VERSION "ChassisCANhs"

NS_ :

BS_:

BU_: CUST USS_ECU HMI PF_PP
VAL_TABLE_ VehStandStill 3 "not used" 2 "Standstill" 1 "no Standstill" 0 "None / unknown" ;
VAL_TABLE_ GearStatus 15 "not used" 14 "not used" 13 "not used" 12 "not used" 11 "not used" 10 "not used" 9 "not used" 8 "not used" 7 "not used" 6 "not used" 5 "not used" 4 "not used" 3 "Drive" 2 "Neutral" 1 "Reverse" 0 "Park" ;
VAL_TABLE_ WheelDirection 3 "not used" 2 "Stop" 1 "Backard" 0 "Forward" ;

BO_ 3221225472 VECTOR__INDEPENDENT_SIG_MSG: 0 Vector__XXX
 SG_ MAP_NumberOfObjects1620 : 0|4@1+ (1,0) [0|15] "" Vector__XXX
 SG_ MAP_20_ObjDist : 0|10@1+ (1,0) [0|1000] "cm" Vector__XXX
 SG_ MAP_19_ObjDist : 0|10@1+ (1,0) [0|1000] "cm" Vector__XXX
 SG_ MAP_18_ObjDist : 0|10@1+ (1,0) [0|1000] "cm" Vector__XXX
 SG_ MAP_17_ObjDist : 0|10@1+ (1,0) [0|1000] "cm" Vector__XXX
 SG_ MAP_16_ObjDist : 0|10@1+ (1,0) [0|1000] "cm" Vector__XXX
 SG_ Multiplex_ID_OBJ_DIST_2 : 0|2@1+ (1,0) [0|0] "" Vector__XXX
 SG_ MAP_06_ObjDist : 0|10@1+ (1,0) [0|1000] "cm" Vector__XXX
 SG_ MAP_NumberOfObjects0610 : 0|4@1+ (1,0) [0|15] "" Vector__XXX
 SG_ MAP_10_ObjDist : 0|10@1+ (1,0) [0|1000] "cm" Vector__XXX
 SG_ MAP_09_ObjDist : 0|10@1+ (1,0) [0|1000] "cm" Vector__XXX
 SG_ MAP_08_ObjDist : 0|10@1+ (1,0) [0|1000] "cm" Vector__XXX
 SG_ MAP_07_ObjDist : 0|10@1+ (1,0) [0|1000] "cm" Vector__XXX
 SG_ MAP_NumberOfObjects0105 : 0|4@1+ (1,0) [0|15] "" Vector__XXX
 SG_ MAP_NumberOfObjects1115 : 0|4@1+ (1,0) [0|15] "" Vector__XXX
 SG_ MAP_15_ObjDist : 0|10@1+ (1,0) [0|1000] "cm" Vector__XXX
 SG_ MAP_14_ObjDist : 0|10@1+ (1,0) [0|1000] "cm" Vector__XXX
 SG_ MAP_13_ObjDist : 0|10@1+ (1,0) [0|1000] "cm" Vector__XXX
 SG_ MAP_12_ObjDist : 0|10@1+ (1,0) [0|1000] "cm" Vector__XXX
 SG_ MAP_11_ObjDist : 0|10@1+ (1,0) [0|1000] "cm" Vector__XXX
 SG_ Multiplex_ID_OBJ_DIST_1 : 0|2@1+ (1,0) [0|0] "" Vector__XXX
 SG_ MAP_05_ObjDist : 0|10@1+ (1,0) [0|1000] "cm" Vector__XXX
 SG_ MAP_04_ObjDist : 0|10@1+ (1,0) [0|1000] "cm" Vector__XXX
 SG_ MAP_03_ObjDist : 0|10@1+ (1,0) [0|1000] "cm" Vector__XXX
 SG_ MAP_02_ObjDist : 0|10@1+ (1,0) [0|1000] "cm" Vector__XXX
 SG_ MAP_01_ObjDist : 0|10@1+ (1,0) [0|1000] "cm" Vector__XXX
 SG_ sens11Amplitude3 : 0|6@1+ (1,0) [0|63] "" Vector__XXX
 SG_ sens11De3Distance : 0|10@1+ (1,0) [0|1023] "cm" Vector__XXX
 SG_ sens10Amplitude3 : 0|6@1+ (1,0) [0|63] "" Vector__XXX
 SG_ sens10De3Distance : 0|10@1+ (1,0) [0|1023] "cm" Vector__XXX
 SG_ sens12Amplitude3 : 0|6@1+ (1,0) [0|63] "" Vector__XXX
 SG_ sens12De3Distance : 0|10@1+ (1,0) [0|1023] "cm" Vector__XXX
 SG_ sens09Amplitude3 : 0|6@1+ (1,0) [0|63] "" Vector__XXX
 SG_ sens09De3Distance : 0|10@1+ (1,0) [0|1023] "cm" Vector__XXX
 SG_ sens08Amplitude3 : 0|6@1+ (1,0) [0|63] "" Vector__XXX
 SG_ sens08De3Distance : 0|10@1+ (1,0) [0|1023] "cm" Vector__XXX
 SG_ sens07Amplitude3 : 0|6@1+ (1,0) [0|63] "" Vector__XXX
 SG_ sens07De3Distance : 0|10@1+ (1,0) [0|1023] "cm" Vector__XXX
 SG_ sens06Amplitude3 : 0|6@1+ (1,0) [0|63] "" Vector__XXX
 SG_ sens06De3Distance : 0|10@1+ (1,0) [0|1023] "cm" Vector__XXX
 SG_ sens05Amplitude3 : 0|6@1+ (1,0) [0|63] "" Vector__XXX
 SG_ sens05De3Distance : 0|10@1+ (1,0) [0|1023] "cm" Vector__XXX
 SG_ sens03De3Distance : 0|10@1+ (1,0) [0|1023] "cm" Vector__XXX
 SG_ sens03Amplitude3 : 0|6@1+ (1,0) [0|63] "" Vector__XXX
 SG_ sens02Amplitude3 : 0|6@1+ (1,0) [0|63] "" Vector__XXX
 SG_ sens02De3Distance : 0|10@1+ (1,0) [0|1023] "cm" Vector__XXX
 SG_ sens04Amplitude3 : 0|6@1+ (1,0) [0|63] "" Vector__XXX
 SG_ sens04De3Distance : 0|10@1+ (1,0) [0|1023] "cm" Vector__XXX
 SG_ sens01Amplitude3 : 0|6@1+ (1,0) [0|63] "" Vector__XXX
 SG_ sens01De3Distance : 0|10@1+ (1,0) [0|1023] "cm" Vector__XXX
 SG_ MAP_13_NewObj : 0|1@1+ (1,0) [0|1] "" Vector__XXX
 SG_ MAP_03_NewObj : 0|1@1+ (1,0) [0|1] "" Vector__XXX
 SG_ MAP_12_NewObj : 0|1@1+ (1,0) [0|1] "" Vector__XXX
 SG_ MAP_02_NewObj : 0|1@1+ (1,0) [0|1] "" Vector__XXX
 SG_ MAP_11_NewObj : 0|1@1+ (1,0) [0|1] "" Vector__XXX
 SG_ MAP_01_NewObj : 0|1@1+ (1,0) [0|1] "" Vector__XXX
 SG_ MAP_20_NewObj : 0|1@1+ (1,0) [0|1] "" Vector__XXX
 SG_ MAP_10_NewObj : 0|1@1+ (1,0) [0|1] "" Vector__XXX
 SG_ MAP_19_NewObj : 0|1@1+ (1,0) [0|1] "" Vector__XXX
 SG_ MAP_09_NewObj : 0|1@1+ (1,0) [0|1] "" Vector__XXX
 SG_ MAP_18_NewObj : 0|1@1+ (1,0) [0|1] "" Vector__XXX
 SG_ MAP_08_NewObj : 0|1@1+ (1,0) [0|1] "" Vector__XXX
 SG_ MAP_17_NewObj : 0|1@1+ (1,0) [0|1] "" Vector__XXX
 SG_ MAP_07_NewObj : 0|1@1+ (1,0) [0|1] "" Vector__XXX
 SG_ MAP_16_NewObj : 0|1@1+ (1,0) [0|1] "" Vector__XXX
 SG_ MAP_06_NewObj : 0|1@1+ (1,0) [0|1] "" Vector__XXX
 SG_ MAP_15_NewObj : 0|1@1+ (1,0) [0|1] "" Vector__XXX
 SG_ MAP_05_NewObj : 0|1@1+ (1,0) [0|1] "" Vector__XXX
 SG_ MAP_14_NewObj : 0|1@1+ (1,0) [0|1] "" Vector__XXX
 SG_ MAP_04_NewObj : 0|1@1+ (1,0) [0|1] "" Vector__XXX
 SG_ MessageCounter_01_Map_Obj_11 : 0|2@1+ (1,0) [0|3] "" Vector__XXX
 SG_ MessageCounter_00_Map_Obj_10 : 0|2@1+ (1,0) [0|3] "" Vector__XXX
 SG_ MessageCounter_00_Map_Obj_09 : 0|2@1+ (1,0) [0|3] "" Vector__XXX
 SG_ MessageCounter_00_Map_Obj_08 : 0|2@1+ (1,0) [0|3] "" Vector__XXX
 SG_ MessageCounter_00_Map_Obj_07 : 0|2@1+ (1,0) [0|3] "" Vector__XXX
 SG_ MessageCounter_00_Map_Obj_06 : 0|2@1+ (1,0) [0|3] "" Vector__XXX
 SG_ MessageCounter_00_Map_Obj_05 : 0|2@1+ (1,0) [0|3] "" Vector__XXX
 SG_ MessageCounter_00_Map_Obj_04 : 0|2@1+ (1,0) [0|3] "" Vector__XXX
 SG_ MessageCounter_00_Map_Obj_03 : 0|2@1+ (1,0) [0|3] "" Vector__XXX
 SG_ MessageCounter_00_Map_Obj_02 : 0|2@1+ (1,0) [0|3] "" Vector__XXX

BO_ 2033 USS_diag_IDs: 8 USS_ECU
 SG_ CanIDDiagResp : 32|32@1+ (1,0) [0|4294967295] "" Vector__XXX
 SG_ CanIDDiagTstReq : 0|32@1+ (1,0) [0|4294967295] "" Vector__XXX

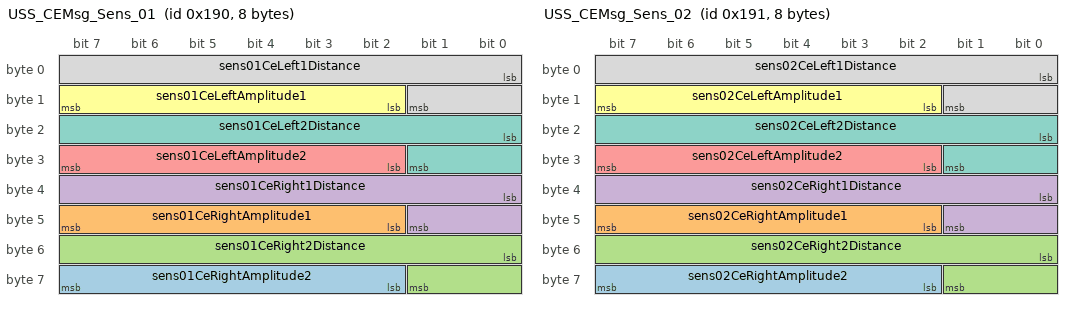
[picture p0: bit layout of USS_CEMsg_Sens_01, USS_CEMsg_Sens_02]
BO_ 400 USS_CEMsg_Sens_01: 8 USS_ECU
 SG_ sens01CeRightAmplitude2 : 58|6@1+ (1,0) [0|63] ""  CUST
 SG_ sens01CeRightAmplitude1 : 42|6@1+ (1,0) [0|63] ""  CUST
 SG_ sens01CeRight2Distance : 48|10@1+ (1,0) [0|1023] "cm"  CUST
 SG_ sens01CeRight1Distance : 32|10@1+ (1,0) [0|1023] "cm"  CUST
 SG_ sens01CeLeftAmplitude2 : 26|6@1+ (1,0) [0|63] ""  CUST
 SG_ sens01CeLeftAmplitude1 : 10|6@1+ (1,0) [0|63] ""  CUST
 SG_ sens01CeLeft2Distance : 16|10@1+ (1,0) [0|1023] "cm"  CUST
 SG_ sens01CeLeft1Distance : 0|10@1+ (1,0) [0|1023] "cm"  CUST

BO_ 401 USS_CEMsg_Sens_02: 8 USS_ECU
 SG_ sens02CeRightAmplitude2 : 58|6@1+ (1,0) [0|63] ""  CUST
 SG_ sens02CeRightAmplitude1 : 42|6@1+ (1,0) [0|63] ""  CUST
 SG_ sens02CeRight2Distance : 48|10@1+ (1,0) [0|1023] "cm"  CUST
 SG_ sens02CeRight1Distance : 32|10@1+ (1,0) [0|1023] "cm"  CUST
 SG_ sens02CeLeftAmplitude2 : 26|6@1+ (1,0) [0|63] ""  CUST
 SG_ sens02CeLeftAmplitude1 : 10|6@1+ (1,0) [0|63] ""  CUST
 SG_ sens02CeLeft2Distance : 16|10@1+ (1,0) [0|1023] "cm"  CUST
 SG_ sens02CeLeft1Distance : 0|10@1+ (1,0) [0|1023] "cm"  CUST

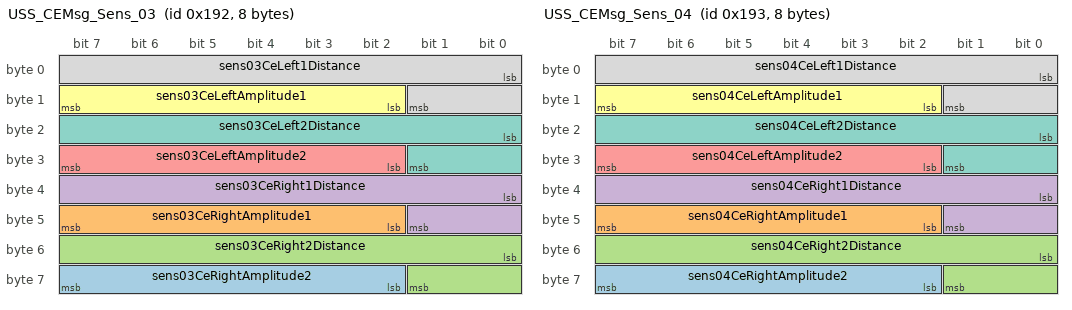
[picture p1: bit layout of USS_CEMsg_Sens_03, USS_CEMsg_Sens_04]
BO_ 402 USS_CEMsg_Sens_03: 8 USS_ECU
 SG_ sens03CeRightAmplitude2 : 58|6@1+ (1,0) [0|63] ""  CUST
 SG_ sens03CeRightAmplitude1 : 42|6@1+ (1,0) [0|63] ""  CUST
 SG_ sens03CeRight2Distance : 48|10@1+ (1,0) [0|1023] "cm"  CUST
 SG_ sens03CeRight1Distance : 32|10@1+ (1,0) [0|1023] "cm"  CUST
 SG_ sens03CeLeftAmplitude2 : 26|6@1+ (1,0) [0|63] ""  CUST
 SG_ sens03CeLeftAmplitude1 : 10|6@1+ (1,0) [0|63] ""  CUST
 SG_ sens03CeLeft2Distance : 16|10@1+ (1,0) [0|1023] "cm"  CUST
 SG_ sens03CeLeft1Distance : 0|10@1+ (1,0) [0|1023] "cm"  CUST

BO_ 403 USS_CEMsg_Sens_04: 8 USS_ECU
 SG_ sens04CeRightAmplitude2 : 58|6@1+ (1,0) [0|63] ""  CUST
 SG_ sens04CeRightAmplitude1 : 42|6@1+ (1,0) [0|63] ""  CUST
 SG_ sens04CeRight2Distance : 48|10@1+ (1,0) [0|1023] "cm"  CUST
 SG_ sens04CeRight1Distance : 32|10@1+ (1,0) [0|1023] "cm"  CUST
 SG_ sens04CeLeftAmplitude2 : 26|6@1+ (1,0) [0|63] ""  CUST
 SG_ sens04CeLeftAmplitude1 : 10|6@1+ (1,0) [0|63] ""  CUST
 SG_ sens04CeLeft2Distance : 16|10@1+ (1,0) [0|1023] "cm"  CUST
 SG_ sens04CeLeft1Distance : 0|10@1+ (1,0) [0|1023] "cm"  CUST

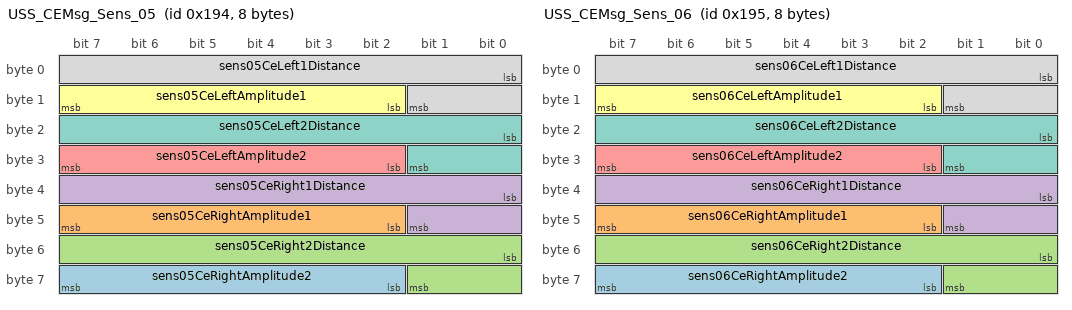
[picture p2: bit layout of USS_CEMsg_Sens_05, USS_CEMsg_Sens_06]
BO_ 404 USS_CEMsg_Sens_05: 8 USS_ECU
 SG_ sens05CeRightAmplitude2 : 58|6@1+ (1,0) [0|63] ""  CUST
 SG_ sens05CeRightAmplitude1 : 42|6@1+ (1,0) [0|63] ""  CUST
 SG_ sens05CeRight2Distance : 48|10@1+ (1,0) [0|1023] "cm"  CUST
 SG_ sens05CeRight1Distance : 32|10@1+ (1,0) [0|1023] "cm"  CUST
 SG_ sens05CeLeftAmplitude2 : 26|6@1+ (1,0) [0|63] ""  CUST
 SG_ sens05CeLeftAmplitude1 : 10|6@1+ (1,0) [0|63] ""  CUST
 SG_ sens05CeLeft2Distance : 16|10@1+ (1,0) [0|1023] "cm"  CUST
 SG_ sens05CeLeft1Distance : 0|10@1+ (1,0) [0|1023] "cm"  CUST

BO_ 405 USS_CEMsg_Sens_06: 8 USS_ECU
 SG_ sens06CeRightAmplitude2 : 58|6@1+ (1,0) [0|63] ""  CUST
 SG_ sens06CeRightAmplitude1 : 42|6@1+ (1,0) [0|63] ""  CUST
 SG_ sens06CeRight2Distance : 48|10@1+ (1,0) [0|1023] "cm"  CUST
 SG_ sens06CeRight1Distance : 32|10@1+ (1,0) [0|1023] "cm"  CUST
 SG_ sens06CeLeftAmplitude2 : 26|6@1+ (1,0) [0|63] ""  CUST
 SG_ sens06CeLeftAmplitude1 : 10|6@1+ (1,0) [0|63] ""  CUST
 SG_ sens06CeLeft2Distance : 16|10@1+ (1,0) [0|1023] "cm"  CUST
 SG_ sens06CeLeft1Distance : 0|10@1+ (1,0) [0|1023] "cm"  CUST

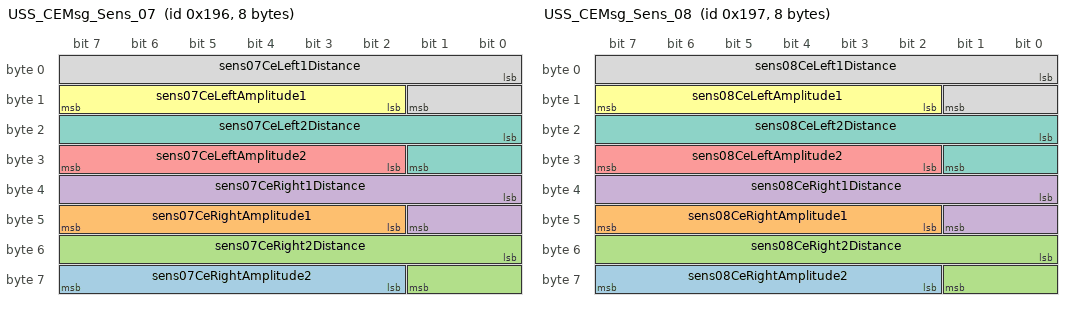
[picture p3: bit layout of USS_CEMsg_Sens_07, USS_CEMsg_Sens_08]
BO_ 406 USS_CEMsg_Sens_07: 8 USS_ECU
 SG_ sens07CeRightAmplitude2 : 58|6@1+ (1,0) [0|63] ""  CUST
 SG_ sens07CeRightAmplitude1 : 42|6@1+ (1,0) [0|63] ""  CUST
 SG_ sens07CeRight2Distance : 48|10@1+ (1,0) [0|1023] "cm"  CUST
 SG_ sens07CeRight1Distance : 32|10@1+ (1,0) [0|1023] "cm"  CUST
 SG_ sens07CeLeftAmplitude2 : 26|6@1+ (1,0) [0|63] ""  CUST
 SG_ sens07CeLeftAmplitude1 : 10|6@1+ (1,0) [0|63] ""  CUST
 SG_ sens07CeLeft2Distance : 16|10@1+ (1,0) [0|1023] "cm"  CUST
 SG_ sens07CeLeft1Distance : 0|10@1+ (1,0) [0|1023] "cm"  CUST

BO_ 407 USS_CEMsg_Sens_08: 8 USS_ECU
 SG_ sens08CeRightAmplitude2 : 58|6@1+ (1,0) [0|63] ""  CUST
 SG_ sens08CeRightAmplitude1 : 42|6@1+ (1,0) [0|63] ""  CUST
 SG_ sens08CeRight2Distance : 48|10@1+ (1,0) [0|1023] "cm"  CUST
 SG_ sens08CeRight1Distance : 32|10@1+ (1,0) [0|1023] "cm"  CUST
 SG_ sens08CeLeftAmplitude2 : 26|6@1+ (1,0) [0|63] ""  CUST
 SG_ sens08CeLeftAmplitude1 : 10|6@1+ (1,0) [0|63] ""  CUST
 SG_ sens08CeLeft2Distance : 16|10@1+ (1,0) [0|1023] "cm"  CUST
 SG_ sens08CeLeft1Distance : 0|10@1+ (1,0) [0|1023] "cm"  CUST

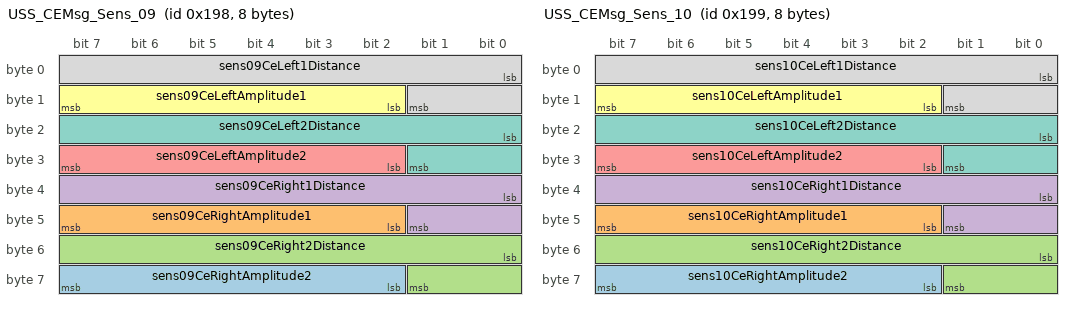
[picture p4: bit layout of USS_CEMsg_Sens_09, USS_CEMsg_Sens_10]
BO_ 408 USS_CEMsg_Sens_09: 8 USS_ECU
 SG_ sens09CeRightAmplitude2 : 58|6@1+ (1,0) [0|63] ""  CUST
 SG_ sens09CeRightAmplitude1 : 42|6@1+ (1,0) [0|63] ""  CUST
 SG_ sens09CeRight2Distance : 48|10@1+ (1,0) [0|1023] "cm"  CUST
 SG_ sens09CeRight1Distance : 32|10@1+ (1,0) [0|1023] "cm"  CUST
 SG_ sens09CeLeftAmplitude2 : 26|6@1+ (1,0) [0|63] ""  CUST
 SG_ sens09CeLeftAmplitude1 : 10|6@1+ (1,0) [0|63] ""  CUST
 SG_ sens09CeLeft2Distance : 16|10@1+ (1,0) [0|1023] "cm"  CUST
 SG_ sens09CeLeft1Distance : 0|10@1+ (1,0) [0|1023] "cm"  CUST

BO_ 409 USS_CEMsg_Sens_10: 8 USS_ECU
 SG_ sens10CeRightAmplitude2 : 58|6@1+ (1,0) [0|63] ""  CUST
 SG_ sens10CeRightAmplitude1 : 42|6@1+ (1,0) [0|63] ""  CUST
 SG_ sens10CeRight2Distance : 48|10@1+ (1,0) [0|1023] "cm"  CUST
 SG_ sens10CeRight1Distance : 32|10@1+ (1,0) [0|1023] "cm"  CUST
 SG_ sens10CeLeftAmplitude2 : 26|6@1+ (1,0) [0|63] ""  CUST
 SG_ sens10CeLeftAmplitude1 : 10|6@1+ (1,0) [0|63] ""  CUST
 SG_ sens10CeLeft2Distance : 16|10@1+ (1,0) [0|1023] "cm"  CUST
 SG_ sens10CeLeft1Distance : 0|10@1+ (1,0) [0|1023] "cm"  CUST

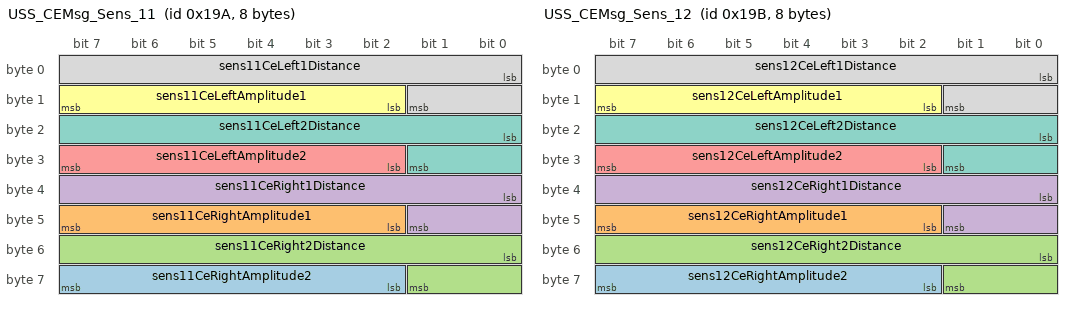
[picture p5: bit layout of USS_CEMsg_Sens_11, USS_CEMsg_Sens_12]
BO_ 410 USS_CEMsg_Sens_11: 8 USS_ECU
 SG_ sens11CeRightAmplitude2 : 58|6@1+ (1,0) [0|63] ""  CUST
 SG_ sens11CeRightAmplitude1 : 42|6@1+ (1,0) [0|63] ""  CUST
 SG_ sens11CeRight2Distance : 48|10@1+ (1,0) [0|1023] "cm"  CUST
 SG_ sens11CeRight1Distance : 32|10@1+ (1,0) [0|1023] "cm"  CUST
 SG_ sens11CeLeftAmplitude2 : 26|6@1+ (1,0) [0|63] ""  CUST
 SG_ sens11CeLeftAmplitude1 : 10|6@1+ (1,0) [0|63] ""  CUST
 SG_ sens11CeLeft2Distance : 16|10@1+ (1,0) [0|1023] "cm"  CUST
 SG_ sens11CeLeft1Distance : 0|10@1+ (1,0) [0|1023] "cm"  CUST

BO_ 411 USS_CEMsg_Sens_12: 8 USS_ECU
 SG_ sens12CeRightAmplitude2 : 58|6@1+ (1,0) [0|63] ""  CUST
 SG_ sens12CeRightAmplitude1 : 42|6@1+ (1,0) [0|63] ""  CUST
 SG_ sens12CeRight2Distance : 48|10@1+ (1,0) [0|1023] "cm"  CUST
 SG_ sens12CeRight1Distance : 32|10@1+ (1,0) [0|1023] "cm"  CUST
 SG_ sens12CeLeftAmplitude2 : 26|6@1+ (1,0) [0|63] ""  CUST
 SG_ sens12CeLeftAmplitude1 : 10|6@1+ (1,0) [0|63] ""  CUST
 SG_ sens12CeLeft2Distance : 16|10@1+ (1,0) [0|1023] "cm"  CUST
 SG_ sens12CeLeft1Distance : 0|10@1+ (1,0) [0|1023] "cm"  CUST

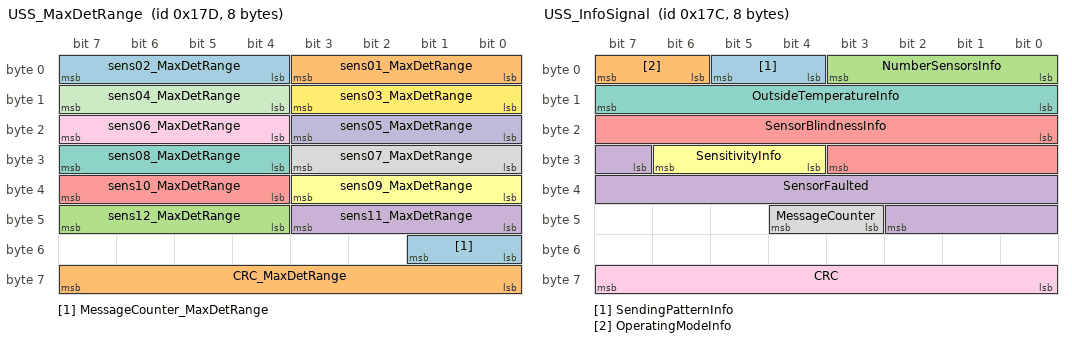
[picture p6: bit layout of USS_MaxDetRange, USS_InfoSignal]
BO_ 381 USS_MaxDetRange: 8 USS_ECU
 SG_ MessageCounter_MaxDetRange : 48|2@1+ (1,0) [0|3] "" Vector__XXX
 SG_ CRC_MaxDetRange : 56|8@1+ (1,0) [0|255] "" Vector__XXX
 SG_ sens12_MaxDetRange : 44|4@1+ (36.667,0) [0|550] ""  CUST
 SG_ sens11_MaxDetRange : 40|4@1+ (36.667,0) [0|550] ""  CUST
 SG_ sens10_MaxDetRange : 36|4@1+ (36.667,0) [0|550] ""  CUST
 SG_ sens09_MaxDetRange : 32|4@1+ (36.667,0) [0|550] ""  CUST
 SG_ sens08_MaxDetRange : 28|4@1+ (36.667,0) [0|550] ""  CUST
 SG_ sens07_MaxDetRange : 24|4@1+ (36.667,0) [0|550] ""  CUST
 SG_ sens06_MaxDetRange : 20|4@1+ (36.667,0) [0|550] ""  CUST
 SG_ sens05_MaxDetRange : 16|4@1+ (36.667,0) [0|550] ""  CUST
 SG_ sens04_MaxDetRange : 12|4@1+ (36.667,0) [0|550] ""  CUST
 SG_ sens03_MaxDetRange : 8|4@1+ (36.667,0) [0|550] ""  CUST
 SG_ sens02_MaxDetRange : 4|4@1+ (36.667,0) [0|550] ""  CUST
 SG_ sens01_MaxDetRange : 0|4@1+ (36.667,0) [0|550.005] ""  CUST

BO_ 380 USS_InfoSignal: 8 USS_ECU
 SG_ SendingPatternInfo : 4|2@1+ (1,0) [0|3] "" Vector__XXX
 SG_ OperatingModeInfo : 6|2@1+ (1,0) [0|3] "" Vector__XXX
 SG_ NumberSensorsInfo : 0|4@1+ (1,0) [0|15] "" Vector__XXX
 SG_ SensorFaulted : 31|12@1+ (1,0) [0|4095] "" Vector__XXX
 SG_ SensorBlindnessInfo : 16|12@1+ (1,0) [0|4095] "" Vector__XXX
 SG_ SensitivityInfo : 28|3@1+ (1,0) [0|7] "" Vector__XXX
 SG_ OutsideTemperatureInfo : 8|8@1+ (1,-40) [-40|215] ""  CUST
 SG_ MessageCounter : 43|2@1+ (1,0) [0|3] ""  CUST
 SG_ CRC : 56|8@1+ (1,0) [0|255] ""  CUST

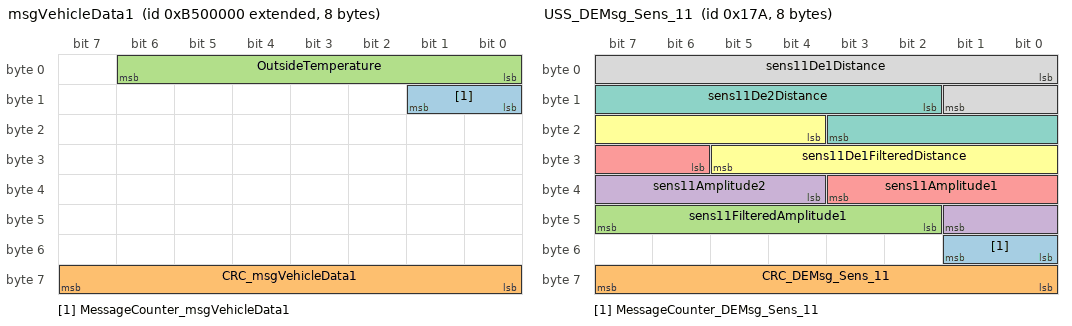
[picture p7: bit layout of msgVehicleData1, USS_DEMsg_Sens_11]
BO_ 2337275904 msgVehicleData1: 8 CUST
 SG_ MessageCounter_msgVehicleData1 : 8|2@1+ (1,0) [0|3] "" Vector__XXX
 SG_ CRC_msgVehicleData1 : 56|8@1+ (1,0) [0|255] "" Vector__XXX
 SG_ OutsideTemperature : 0|7@1+ (1,-40) [-40|85] "°C"  USS_ECU

BO_ 378 USS_DEMsg_Sens_11: 8 USS_ECU
 SG_ MessageCounter_DEMsg_Sens_11 : 48|2@1+ (1,0) [0|3] "" Vector__XXX
 SG_ CRC_DEMsg_Sens_11 : 56|8@1+ (1,0) [0|255] "" Vector__XXX
 SG_ sens11FilteredAmplitude1 : 42|6@1+ (1,0) [0|63] ""  CUST
 SG_ sens11Amplitude2 : 36|6@1+ (1,0) [0|63] ""  CUST
 SG_ sens11Amplitude1 : 30|6@1+ (1,0) [0|63] ""  CUST
 SG_ sens11De1FilteredDistance : 20|10@1+ (1,0) [0|1023] "cm"  CUST
 SG_ sens11De2Distance : 10|10@1+ (1,0) [0|1023] "cm"  CUST
 SG_ sens11De1Distance : 0|10@1+ (1,0) [0|1023] "cm"  CUST

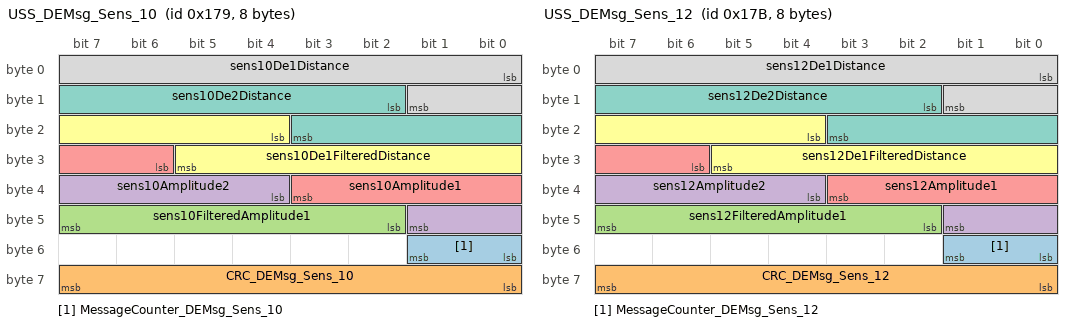
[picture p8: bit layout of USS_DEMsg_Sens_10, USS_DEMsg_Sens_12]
BO_ 377 USS_DEMsg_Sens_10: 8 USS_ECU
 SG_ MessageCounter_DEMsg_Sens_10 : 48|2@1+ (1,0) [0|3] "" Vector__XXX
 SG_ CRC_DEMsg_Sens_10 : 56|8@1+ (1,0) [0|255] "" Vector__XXX
 SG_ sens10FilteredAmplitude1 : 42|6@1+ (1,0) [0|63] ""  CUST
 SG_ sens10Amplitude2 : 36|6@1+ (1,0) [0|63] ""  CUST
 SG_ sens10Amplitude1 : 30|6@1+ (1,0) [0|63] ""  CUST
 SG_ sens10De1FilteredDistance : 20|10@1+ (1,0) [0|1023] "cm"  CUST
 SG_ sens10De2Distance : 10|10@1+ (1,0) [0|1023] "cm"  CUST
 SG_ sens10De1Distance : 0|10@1+ (1,0) [0|1023] "cm"  CUST

BO_ 379 USS_DEMsg_Sens_12: 8 USS_ECU
 SG_ MessageCounter_DEMsg_Sens_12 : 48|2@1+ (1,0) [0|3] "" Vector__XXX
 SG_ CRC_DEMsg_Sens_12 : 56|8@1+ (1,0) [0|255] "" Vector__XXX
 SG_ sens12FilteredAmplitude1 : 42|6@1+ (1,0) [0|63] ""  CUST
 SG_ sens12Amplitude2 : 36|6@1+ (1,0) [0|63] ""  CUST
 SG_ sens12Amplitude1 : 30|6@1+ (1,0) [0|63] ""  CUST
 SG_ sens12De1FilteredDistance : 20|10@1+ (1,0) [0|1023] "cm"  CUST
 SG_ sens12De2Distance : 10|10@1+ (1,0) [0|1023] "cm"  CUST
 SG_ sens12De1Distance : 0|10@1+ (1,0) [0|1023] "cm"  CUST

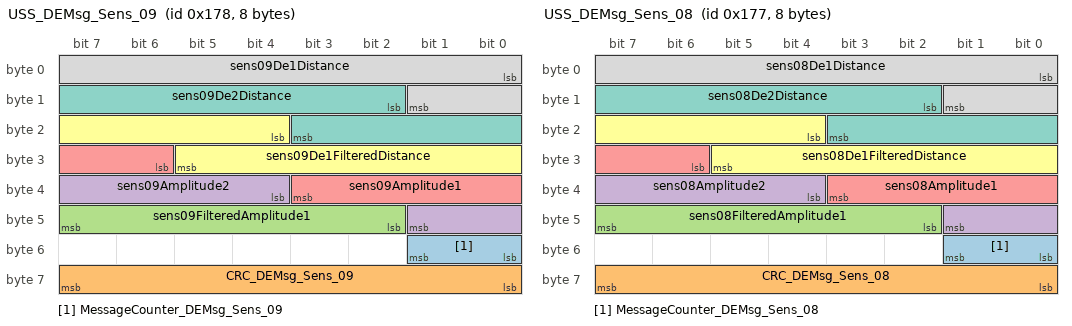
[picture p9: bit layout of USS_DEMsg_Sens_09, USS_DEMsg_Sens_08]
BO_ 376 USS_DEMsg_Sens_09: 8 USS_ECU
 SG_ MessageCounter_DEMsg_Sens_09 : 48|2@1+ (1,0) [0|3] "" Vector__XXX
 SG_ CRC_DEMsg_Sens_09 : 56|8@1+ (1,0) [0|255] "" Vector__XXX
 SG_ sens09FilteredAmplitude1 : 42|6@1+ (1,0) [0|63] ""  CUST
 SG_ sens09Amplitude2 : 36|6@1+ (1,0) [0|63] ""  CUST
 SG_ sens09Amplitude1 : 30|6@1+ (1,0) [0|63] ""  CUST
 SG_ sens09De1FilteredDistance : 20|10@1+ (1,0) [0|1023] "cm"  CUST
 SG_ sens09De2Distance : 10|10@1+ (1,0) [0|1023] "cm"  CUST
 SG_ sens09De1Distance : 0|10@1+ (1,0) [0|1023] "cm"  CUST

BO_ 375 USS_DEMsg_Sens_08: 8 USS_ECU
 SG_ MessageCounter_DEMsg_Sens_08 : 48|2@1+ (1,0) [0|3] "" Vector__XXX
 SG_ CRC_DEMsg_Sens_08 : 56|8@1+ (1,0) [0|255] "" Vector__XXX
 SG_ sens08FilteredAmplitude1 : 42|6@1+ (1,0) [0|63] ""  CUST
 SG_ sens08Amplitude2 : 36|6@1+ (1,0) [0|63] ""  CUST
 SG_ sens08Amplitude1 : 30|6@1+ (1,0) [0|63] ""  CUST
 SG_ sens08De1FilteredDistance : 20|10@1+ (1,0) [0|1023] "cm"  CUST
 SG_ sens08De2Distance : 10|10@1+ (1,0) [0|1023] "cm"  CUST
 SG_ sens08De1Distance : 0|10@1+ (1,0) [0|1023] "cm"  CUST

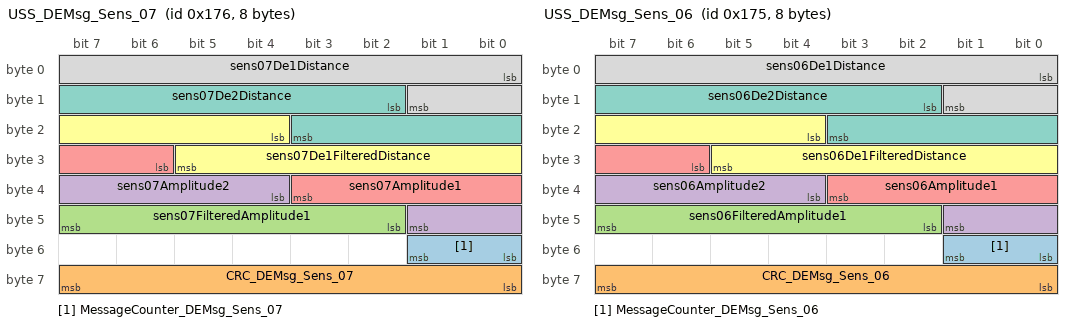
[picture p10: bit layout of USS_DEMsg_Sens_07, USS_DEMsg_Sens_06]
BO_ 374 USS_DEMsg_Sens_07: 8 USS_ECU
 SG_ MessageCounter_DEMsg_Sens_07 : 48|2@1+ (1,0) [0|3] "" Vector__XXX
 SG_ CRC_DEMsg_Sens_07 : 56|8@1+ (1,0) [0|255] "" Vector__XXX
 SG_ sens07FilteredAmplitude1 : 42|6@1+ (1,0) [0|63] ""  CUST
 SG_ sens07Amplitude2 : 36|6@1+ (1,0) [0|63] ""  CUST
 SG_ sens07Amplitude1 : 30|6@1+ (1,0) [0|63] ""  CUST
 SG_ sens07De1FilteredDistance : 20|10@1+ (1,0) [0|1023] "cm"  CUST
 SG_ sens07De2Distance : 10|10@1+ (1,0) [0|1023] "cm"  CUST
 SG_ sens07De1Distance : 0|10@1+ (1,0) [0|1023] "cm"  CUST

BO_ 373 USS_DEMsg_Sens_06: 8 USS_ECU
 SG_ MessageCounter_DEMsg_Sens_06 : 48|2@1+ (1,0) [0|3] "" Vector__XXX
 SG_ CRC_DEMsg_Sens_06 : 56|8@1+ (1,0) [0|255] "" Vector__XXX
 SG_ sens06FilteredAmplitude1 : 42|6@1+ (1,0) [0|63] ""  CUST
 SG_ sens06Amplitude2 : 36|6@1+ (1,0) [0|63] ""  CUST
 SG_ sens06Amplitude1 : 30|6@1+ (1,0) [0|63] ""  CUST
 SG_ sens06De1FilteredDistance : 20|10@1+ (1,0) [0|1023] "cm"  CUST
 SG_ sens06De2Distance : 10|10@1+ (1,0) [0|1023] "cm"  CUST
 SG_ sens06De1Distance : 0|10@1+ (1,0) [0|1023] "cm"  CUST

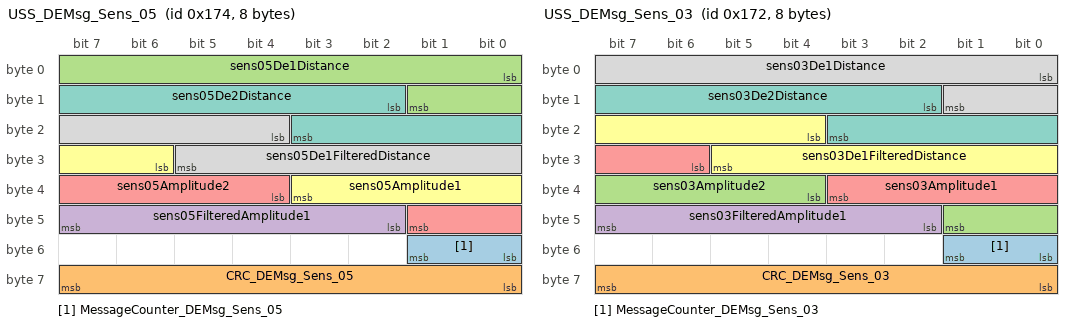
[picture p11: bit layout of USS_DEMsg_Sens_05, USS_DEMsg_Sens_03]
BO_ 372 USS_DEMsg_Sens_05: 8 USS_ECU
 SG_ MessageCounter_DEMsg_Sens_05 : 48|2@1+ (1,0) [0|3] "" Vector__XXX
 SG_ CRC_DEMsg_Sens_05 : 56|8@1+ (1,0) [0|255] "" Vector__XXX
 SG_ sens05De1Distance : 0|10@1+ (1,0) [0|1023] "cm"  CUST
 SG_ sens05FilteredAmplitude1 : 42|6@1+ (1,0) [0|63] ""  CUST
 SG_ sens05Amplitude2 : 36|6@1+ (1,0) [0|63] ""  CUST
 SG_ sens05Amplitude1 : 30|6@1+ (1,0) [0|63] ""  CUST
 SG_ sens05De2Distance : 10|10@1+ (1,0) [0|1023] "cm"  CUST
 SG_ sens05De1FilteredDistance : 20|10@1+ (1,0) [0|1023] "cm"  CUST

BO_ 370 USS_DEMsg_Sens_03: 8 USS_ECU
 SG_ MessageCounter_DEMsg_Sens_03 : 48|2@1+ (1,0) [0|3] "" Vector__XXX
 SG_ CRC_DEMsg_Sens_03 : 56|8@1+ (1,0) [0|255] "" Vector__XXX
 SG_ sens03Amplitude2 : 36|6@1+ (1,0) [0|63] "" Vector__XXX
 SG_ sens03FilteredAmplitude1 : 42|6@1+ (1,0) [0|63] ""  CUST
 SG_ sens03Amplitude1 : 30|6@1+ (1,0) [0|63] ""  CUST
 SG_ sens03De1FilteredDistance : 20|10@1+ (1,0) [0|1023] "cm"  CUST
 SG_ sens03De2Distance : 10|10@1+ (1,0) [0|1023] "cm"  CUST
 SG_ sens03De1Distance : 0|10@1+ (1,0) [0|1023] "cm"  CUST

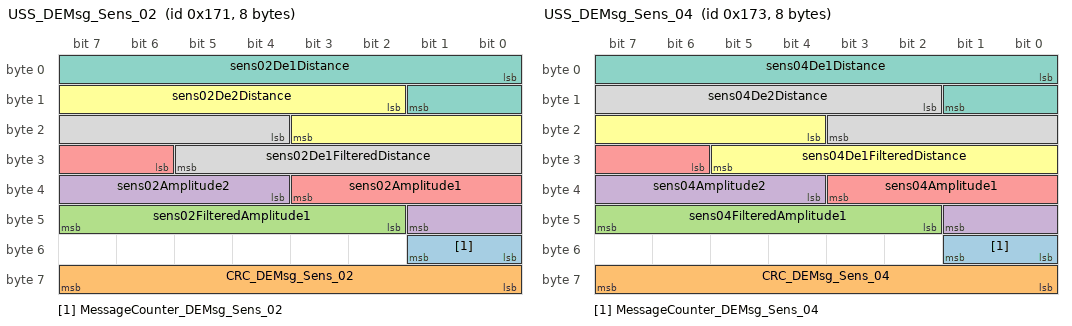
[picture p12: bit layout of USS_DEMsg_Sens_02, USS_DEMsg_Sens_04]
BO_ 369 USS_DEMsg_Sens_02: 8 USS_ECU
 SG_ MessageCounter_DEMsg_Sens_02 : 48|2@1+ (1,0) [0|3] "" Vector__XXX
 SG_ CRC_DEMsg_Sens_02 : 56|8@1+ (1,0) [0|255] "" Vector__XXX
 SG_ sens02FilteredAmplitude1 : 42|6@1+ (1,0) [0|63] ""  CUST
 SG_ sens02Amplitude2 : 36|6@1+ (1,0) [0|63] ""  CUST
 SG_ sens02Amplitude1 : 30|6@1+ (1,0) [0|63] ""  CUST
 SG_ sens02De2Distance : 10|10@1+ (1,0) [0|1023] "cm"  CUST
 SG_ sens02De1Distance : 0|10@1+ (1,0) [0|1023] "cm"  CUST
 SG_ sens02De1FilteredDistance : 20|10@1+ (1,0) [0|1023] "cm"  CUST

BO_ 371 USS_DEMsg_Sens_04: 8 USS_ECU
 SG_ MessageCounter_DEMsg_Sens_04 : 48|2@1+ (1,0) [0|3] "" Vector__XXX
 SG_ CRC_DEMsg_Sens_04 : 56|8@1+ (1,0) [0|255] "" Vector__XXX
 SG_ sens04FilteredAmplitude1 : 42|6@1+ (1,0) [0|63] ""  CUST
 SG_ sens04Amplitude2 : 36|6@1+ (1,0) [0|63] ""  CUST
 SG_ sens04Amplitude1 : 30|6@1+ (1,0) [0|63] ""  CUST
 SG_ sens04De1FilteredDistance : 20|10@1+ (1,0) [0|1023] "cm"  CUST
 SG_ sens04De1Distance : 0|10@1+ (1,0) [0|1023] "cm"  CUST
 SG_ sens04De2Distance : 10|10@1+ (1,0) [0|1023] "cm"  CUST

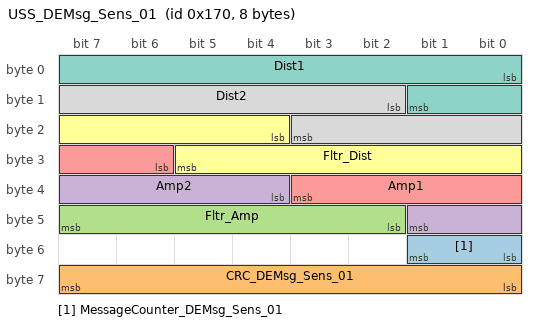
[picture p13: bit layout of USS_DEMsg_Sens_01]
BO_ 368 USS_DEMsg_Sens_01: 8 USS_ECU
 SG_ MessageCounter_DEMsg_Sens_01 : 48|2@1+ (1,0) [0|3] "" Vector__XXX
 SG_ CRC_DEMsg_Sens_01 : 56|8@1+ (1,0) [0|255] "" Vector__XXX
 SG_ Fltr_Amp : 42|6@1+ (1,0) [0|63] ""  CUST
 SG_ Amp2 : 36|6@1+ (1,0) [0|63] ""  CUST
 SG_ Amp1 : 30|6@1+ (1,0) [0|63] ""  CUST
 SG_ Fltr_Dist : 20|10@1+ (1,0) [0|1023] "cm"  CUST
 SG_ Dist1 : 0|10@1+ (1,0) [0|1023] "cm"  CUST
 SG_ Dist2 : 10|10@1+ (1,0) [0|1023] "cm"  CU

BO_ 393 USS_MAP_OBJ_10: 8 PF_PP
 SG_ MessageCounter_Map_Obj_10 : 54|2@1+ (1,0) [0|3] "" Vector__XXX
 SG_ CRC_01_Map_Obj_20 m1 : 56|8@1+ (1,0) [0|255] "" Vector__XXX
 SG_ CRC_00_Map_Obj_10 m0 : 56|8@1+ (1,0) [0|255] "" Vector__XXX
 SG_ MAP_20_ObjectType m1 : 44|2@1+ (1,0) [0|15] ""  HMI
 SG_ MAP_20_Obj_ID m1 : 46|8@1+ (1,0) [0|255] ""  HMI
 SG_ MAP_20_ExistProbability m1 : 20|3@1+ (1,0) [0|15] ""  HMI
 SG_ MAP_20_2ndPointY m1 : 33|10@1- (2,0) [-1024|1022] "cm"  HMI
 SG_ MAP_20_2ndPointX m1 : 23|10@1- (2,0) [-1024|1022] "cm"  HMI
 SG_ MAP_20_1stPointY m1 : 10|10@1- (2,0) [-1024|1022] "cm"  HMI
 SG_ MAP_20_1stPointX m1 : 0|10@1- (2,0) [-1024|1022] "cm"  HMI
 SG_ Multiplex_ID_10 M : 43|1@1+ (1,0) [0|0] ""  HMI
 SG_ MAP_10_ObjectType m0 : 44|2@1+ (1,0) [0|15] ""  HMI
 SG_ MAP_10_Obj_ID m0 : 46|8@1+ (1,0) [0|255] ""  HMI
 SG_ MAP_10_ExistProbability m0 : 20|3@1+ (1,0) [0|15] ""  HMI
 SG_ MAP_10_2ndPointY m0 : 33|10@1- (2,0) [-1024|1022] "cm"  HMI
 SG_ MAP_10_2ndPointX m0 : 23|10@1- (2,0) [-1024|1022] "cm"  HMI
 SG_ MAP_10_1stPointY m0 : 10|10@1- (2,0) [-1024|1022] "cm"  HMI
 SG_ MAP_10_1stPointX m0 : 0|10@1- (2,0) [-1024|1022] "cm"  HMI

BO_ 392 USS_MAP_OBJ_09: 8 PF_PP
 SG_ MessageCounter_Map_Obj_09 : 54|2@1+ (1,0) [0|3] "" Vector__XXX
 SG_ CRC_01_Map_Obj_19 m1 : 56|8@1+ (1,0) [0|255] "" Vector__XXX
 SG_ CRC_00_Map_Obj_09 m0 : 56|8@1+ (1,0) [0|255] "" Vector__XXX
 SG_ MAP_19_ObjectType m1 : 44|2@1+ (1,0) [0|15] ""  HMI
 SG_ MAP_19_Obj_ID m1 : 46|8@1+ (1,0) [0|255] ""  HMI
 SG_ MAP_19_ExistProbability m1 : 20|3@1+ (1,0) [0|7] ""  HMI
 SG_ MAP_19_2ndPointY m1 : 33|10@1- (2,0) [-1024|1022] "cm"  HMI
 SG_ MAP_19_2ndPointX m1 : 23|10@1- (2,0) [-1024|1022] "cm"  HMI
 SG_ MAP_19_1stPointY m1 : 10|10@1- (2,0) [-1024|1022] "cm"  HMI
 SG_ MAP_19_1stPointX m1 : 0|10@1- (2,0) [-1024|1022] "cm"  HMI
 SG_ Multiplex_ID_09 M : 43|1@1+ (1,0) [0|1] ""  HMI
 SG_ MAP_09_ObjectType m0 : 44|2@1+ (1,0) [0|15] ""  HMI
 SG_ MAP_09_Obj_ID m0 : 46|8@1+ (1,0) [0|255] ""  HMI
 SG_ MAP_09_ExistProbability m0 : 20|3@1+ (1,0) [0|7] ""  HMI
 SG_ MAP_09_2ndPointY m0 : 33|10@1- (2,0) [-1024|1022] "cm"  HMI
 SG_ MAP_09_2ndPointX m0 : 23|10@1- (2,0) [-1024|1022] "cm"  HMI
 SG_ MAP_09_1stPointY m0 : 10|10@1- (2,0) [-1024|1022] "cm"  HMI
 SG_ MAP_09_1stPointX m0 : 0|10@1- (2,0) [-1024|1022] "cm"  HMI

BO_ 391 USS_MAP_OBJ_08: 8 PF_PP
 SG_ MessageCounter_Map_Obj_08 : 54|2@1+ (1,0) [0|3] "" Vector__XXX
 SG_ CRC_01_Map_Obj_18 m1 : 56|8@1+ (1,0) [0|255] "" Vector__XXX
 SG_ CRC_00_Map_Obj_08 m0 : 56|8@1+ (1,0) [0|255] "" Vector__XXX
 SG_ MAP_18_ObjectType m1 : 44|2@1+ (1,0) [0|15] ""  HMI
 SG_ MAP_18_Obj_ID m1 : 46|8@1+ (1,0) [0|255] ""  HMI
 SG_ MAP_18_ExistProbability m1 : 20|3@1+ (1,0) [0|15] ""  HMI
 SG_ MAP_18_2ndPointY m1 : 33|10@1- (2,0) [-1024|1022] "cm"  HMI
 SG_ MAP_18_2ndPointX m1 : 23|10@1- (2,0) [-1024|1022] "cm"  HMI
 SG_ MAP_18_1stPointY m1 : 10|10@1- (2,0) [-1024|1022] "cm"  HMI
 SG_ MAP_18_1stPointX m1 : 0|10@1- (2,0) [-1024|1022] "cm"  HMI
 SG_ Multiplex_ID_08 M : 43|1@1+ (1,0) [0|1] ""  HMI
 SG_ MAP_08_ObjectType m0 : 44|2@1+ (1,0) [0|15] ""  HMI
 SG_ MAP_08_Obj_ID m0 : 46|8@1+ (1,0) [0|255] ""  HMI
 SG_ MAP_08_ExistProbability m0 : 20|3@1+ (1,0) [0|15] ""  HMI
 SG_ MAP_08_2ndPointY m0 : 33|10@1- (2,0) [-1024|1022] "cm"  HMI
 SG_ MAP_08_2ndPointX m0 : 23|10@1- (2,0) [-1024|1022] "cm"  HMI
 SG_ MAP_08_1stPointY m0 : 10|10@1- (2,0) [-1024|1022] "cm"  HMI
 SG_ MAP_08_1stPointX m0 : 0|10@1- (2,0) [-1024|1022] "cm"  HMI

BO_ 390 USS_MAP_OBJ_07: 8 PF_PP
 SG_ MessageCounter_Map_Obj_07 : 54|2@1+ (1,0) [0|3] "" Vector__XXX
 SG_ CRC_01_Map_Obj_17 m1 : 56|8@1+ (1,0) [0|255] "" Vector__XXX
 SG_ CRC_00_Map_Obj_07 m0 : 56|8@1+ (1,0) [0|255] "" Vector__XXX
 SG_ MAP_17_ObjectType m1 : 44|2@1+ (1,0) [0|3] ""  HMI
 SG_ MAP_17_Obj_ID m1 : 46|8@1+ (1,0) [0|255] ""  HMI
 SG_ MAP_17_ExistProbability m1 : 20|3@1+ (1,0) [0|15] ""  HMI
 SG_ MAP_17_2ndPointY m1 : 33|10@1- (2,0) [-1024|1022] "cm"  HMI
 SG_ MAP_17_2ndPointX m1 : 23|10@1- (2,0) [-1024|1022] "cm"  HMI
 SG_ MAP_17_1stPointY m1 : 10|10@1- (2,0) [-1024|1022] "cm"  HMI
 SG_ MAP_17_1stPointX m1 : 0|10@1- (2,0) [-1024|1022] "cm"  HMI
 SG_ Multiplex_ID_07 M : 43|1@1+ (1,0) [0|0] ""  HMI
 SG_ MAP_07_ObjectType m0 : 44|2@1+ (1,0) [0|15] ""  HMI
 SG_ MAP_07_Obj_ID m0 : 46|8@1+ (1,0) [0|255] ""  HMI
 SG_ MAP_07_ExistProbability m0 : 20|3@1+ (1,0) [0|15] ""  HMI
 SG_ MAP_07_2ndPointY m0 : 33|10@1- (2,0) [-1024|1022] "cm"  HMI
 SG_ MAP_07_2ndPointX m0 : 23|10@1- (2,0) [-1024|1022] "cm"  HMI
 SG_ MAP_07_1stPointY m0 : 10|10@1- (2,0) [-1024|1022] "cm"  HMI
 SG_ MAP_07_1stPointX m0 : 0|10@1- (2,0) [-1024|1022] "cm"  HMI

BO_ 389 USS_MAP_OBJ_06: 8 PF_PP
 SG_ MessageCounter_Map_Obj_06 : 54|2@1+ (1,0) [0|3] "" Vector__XXX
 SG_ CRC_01_Map_Obj_16 m1 : 56|8@1+ (1,0) [0|255] "" Vector__XXX
 SG_ CRC_00_Map_Obj_06 m0 : 56|8@1+ (1,0) [0|255] "" Vector__XXX
 SG_ MAP_06_Obj_ID m0 : 46|8@1+ (1,0) [0|255] ""  HMI
 SG_ MAP_16_ObjectType m1 : 44|2@1+ (1,0) [0|3] ""  HMI
 SG_ MAP_16_Obj_ID m1 : 46|8@1+ (1,0) [0|255] ""  HMI
 SG_ MAP_16_ExistProbability m1 : 20|3@1+ (1,0) [0|7] ""  HMI
 SG_ MAP_16_2ndPointY m1 : 33|10@1- (2,0) [-1024|1022] "cm"  HMI
 SG_ MAP_16_2ndPointX m1 : 23|10@1- (2,0) [-1024|1022] "cm"  HMI
 SG_ MAP_16_1stPointY m1 : 10|10@1- (2,0) [-1024|1022] "cm"  HMI
 SG_ MAP_16_1stPointX m1 : 0|10@1- (2,0) [-1024|1022] "cm"  HMI
 SG_ Multiplex_ID_06 M : 43|1@1+ (1,0) [0|1] ""  HMI
 SG_ MAP_06_ObjectType m0 : 44|2@1+ (1,0) [0|15] ""  HMI
 SG_ MAP_06_ExistProbability m0 : 20|3@1+ (1,0) [0|7] ""  HMI
 SG_ MAP_06_2ndPointY m0 : 33|10@1- (2,0) [-1024|1022] "cm"  HMI
 SG_ MAP_06_2ndPointX m0 : 23|10@1- (2,0) [-1024|1022] "cm"  HMI
 SG_ MAP_06_1stPointY m0 : 10|10@1- (2,0) [-1024|1022] "cm"  HMI
 SG_ MAP_06_1stPointX m0 : 0|10@1- (2,0) [-1024|1022] "cm"  HMI

BO_ 388 USS_MAP_OBJ_05: 8 PF_PP
 SG_ MessageCounter_Map_Obj_05 : 54|2@1+ (1,0) [0|3] "" Vector__XXX
 SG_ CRC_01_Map_Obj_15 m1 : 56|8@1+ (1,0) [0|255] "" Vector__XXX
 SG_ CRC_00_Map_Obj_05 m0 : 56|8@1+ (1,0) [0|255] "" Vector__XXX
 SG_ MAP_15_ObjectType m1 : 44|2@1+ (1,0) [0|15] ""  HMI
 SG_ MAP_15_Obj_ID m1 : 46|8@1+ (1,0) [0|255] ""  HMI
 SG_ MAP_15_ExistProbability m1 : 20|3@1+ (1,0) [0|15] ""  HMI
 SG_ MAP_15_2ndPointY m1 : 33|10@1- (2,0) [-1024|1022] "cm"  HMI
 SG_ MAP_15_2ndPointX m1 : 23|10@1- (2,0) [-1024|1022] "cm"  HMI
 SG_ MAP_15_1stPointY m1 : 10|10@1- (2,0) [-1024|1022] "cm"  HMI
 SG_ MAP_15_1stPointX m1 : 0|10@1- (2,0) [-1024|1022] "cm"  HMI
 SG_ Multiplex_ID_05 M : 43|1@1+ (1,0) [0|1] ""  HMI
 SG_ MAP_05_ObjectType m0 : 44|2@1+ (1,0) [0|7] ""  HMI
 SG_ MAP_05_Obj_ID m0 : 46|8@1+ (1,0) [0|255] ""  HMI
 SG_ MAP_05_ExistProbability m0 : 20|3@1+ (1,0) [0|15] ""  HMI
 SG_ MAP_05_2ndPointY m0 : 33|10@1- (2,0) [-1024|1022] "cm"  HMI
 SG_ MAP_05_2ndPointX m0 : 23|10@1- (2,0) [-1024|1022] "cm"  HMI
 SG_ MAP_05_1stPointY m0 : 10|10@1- (2,0) [-1024|1022] "cm"  HMI
 SG_ MAP_05_1stPointX m0 : 0|10@1- (2,0) [-1024|1022] "cm"  HMI

BO_ 387 USS_MAP_OBJ_04: 8 PF_PP
 SG_ MessageCounter_Map_Obj_04 : 54|2@1+ (1,0) [0|3] "" Vector__XXX
 SG_ CRC_01_Map_Obj_14 m1 : 56|8@1+ (1,0) [0|255] "" Vector__XXX
 SG_ CRC_00_Map_Obj_04 m0 : 56|8@1+ (1,0) [0|255] "" Vector__XXX
 SG_ MAP_14_ObjectType m1 : 44|2@1+ (1,0) [0|15] ""  HMI
 SG_ MAP_14_Obj_ID m1 : 46|8@1+ (1,0) [0|255] ""  HMI
 SG_ MAP_14_ExistProbability m1 : 20|3@1+ (1,0) [0|15] ""  HMI
 SG_ MAP_14_2ndPointY m1 : 33|10@1- (2,0) [-1024|1022] "cm"  HMI
 SG_ MAP_14_2ndPointX m1 : 23|10@1- (2,0) [-1024|1022] "cm"  HMI
 SG_ MAP_14_1stPointY m1 : 10|10@1- (2,0) [-1024|1022] "cm"  HMI
 SG_ MAP_14_1stPointX m1 : 0|10@1- (2,0) [-1024|1022] "cm"  HMI
 SG_ Multiplex_ID_04 M : 43|1@1+ (1,0) [0|1] ""  HMI
 SG_ MAP_04_ObjectType m0 : 44|2@1+ (1,0) [0|3] ""  HMI
 SG_ MAP_04_Obj_ID m0 : 46|8@1+ (1,0) [0|255] ""  HMI
 SG_ MAP_04_ExistProbability m0 : 20|3@1+ (1,0) [0|7] ""  HMI
 SG_ MAP_04_2ndPointY m0 : 33|10@1- (2,0) [-1024|1022] "cm"  HMI
 SG_ MAP_04_2ndPointX m0 : 23|10@1- (2,0) [-1024|1022] "cm"  HMI
 SG_ MAP_04_1stPointY m0 : 10|10@1- (2,0) [-1024|1022] "cm"  HMI
 SG_ MAP_04_1stPointX m0 : 0|10@1- (2,0) [-1024|1022] "cm"  HMI

BO_ 386 USS_MAP_OBJ_03: 8 PF_PP
 SG_ Multiplex_ID_03 M : 43|1@1+ (1,0) [0|1] ""  HMI
 SG_ MAP_03_Obj_ID m0 : 46|8@1+ (1,0) [0|255] ""  HMI
 SG_ MessageCounter_Map_Obj_03 : 54|2@1+ (1,0) [0|3] "" Vector__XXX
 SG_ CRC_01_Map_Obj_13 m1 : 56|8@1+ (1,0) [0|255] "" Vector__XXX
 SG_ CRC_00_Map_Obj_03 m0 : 56|8@1+ (1,0) [0|255] "" Vector__XXX
 SG_ MAP_13_ObjectType m1 : 44|2@1+ (1,0) [0|15] ""  HMI
 SG_ MAP_13_Obj_ID m1 : 46|8@1+ (1,0) [0|255] ""  HMI
 SG_ MAP_13_ExistProbability m1 : 20|3@1+ (1,0) [0|7] ""  HMI
 SG_ MAP_13_2ndPointY m1 : 33|10@1- (2,0) [-1024|1022] "cm"  HMI
 SG_ MAP_13_2ndPointX m1 : 23|10@1- (2,0) [-1024|1022] "cm"  HMI
 SG_ MAP_13_1stPointY m1 : 10|10@1- (2,0) [-1024|1022] "cm"  HMI
 SG_ MAP_13_1stPointX m1 : 0|10@1- (2,0) [-1024|1022] "cm"  HMI
 SG_ MAP_03_ObjectType m0 : 44|2@1+ (1,0) [0|3] ""  HMI
 SG_ MAP_03_ExistProbability m0 : 20|3@1+ (1,0) [0|7] ""  HMI
 SG_ MAP_03_2ndPointY m0 : 33|10@1- (2,0) [-1024|1022] "cm"  HMI
 SG_ MAP_03_2ndPointX m0 : 23|10@1- (2,0) [-1024|1022] "cm"  HMI
 SG_ MAP_03_1stPointY m0 : 10|10@1- (2,0) [-1024|1022] "cm"  HMI
 SG_ MAP_03_1stPointX m0 : 0|10@1- (2,0) [-1024|1022] "cm"  HMI

BO_ 385 USS_MAP_OBJ_02: 8 PF_PP
 SG_ MessageCounter_Map_Obj_02 : 54|2@1+ (1,0) [0|3] "" Vector__XXX
 SG_ CRC_01_Map_Obj_12 m1 : 56|8@1+ (1,0) [0|255] "" Vector__XXX
 SG_ CRC_00_Map_Obj_02 m0 : 56|8@1+ (1,0) [0|255] "" Vector__XXX
 SG_ MAP_12_ObjectType m1 : 44|2@1+ (1,0) [0|15] ""  HMI
 SG_ MAP_12_Obj_ID m1 : 46|8@1+ (1,0) [0|255] ""  HMI
 SG_ MAP_12_ExistProbability m1 : 20|3@1+ (1,0) [0|7] ""  HMI
 SG_ MAP_12_2ndPointY m1 : 33|10@1- (2,0) [-1024|1022] "cm"  HMI
 SG_ MAP_12_2ndPointX m1 : 23|10@1- (2,0) [-1024|1022] "cm"  HMI
 SG_ MAP_12_1stPointY m1 : 10|10@1- (2,0) [-1024|1022] "cm"  HMI
 SG_ MAP_12_1stPointX m1 : 0|10@1- (2,0) [-1024|1022] "cm"  HMI
 SG_ Multiplex_ID_02 M : 43|1@1+ (1,0) [0|1] ""  HMI
 SG_ MAP_02_ObjectType m0 : 44|2@1+ (1,0) [0|15] ""  HMI
 SG_ MAP_02_Obj_ID m0 : 46|8@1+ (1,0) [0|255] ""  HMI
 SG_ MAP_02_ExistProbability m0 : 20|3@1+ (1,0) [0|15] ""  HMI
 SG_ MAP_02_2ndPointY m0 : 33|10@1- (2,0) [-1024|1022] "cm"  HMI
 SG_ MAP_02_2ndPointX m0 : 23|10@1- (2,0) [-1024|1022] "cm"  HMI
 SG_ MAP_02_1stPointY m0 : 10|10@1- (2,0) [-1024|1022] "cm"  HMI
 SG_ MAP_02_1stPointX m0 : 0|10@1- (2,0) [-1024|1022] "cm"  HMI

BO_ 384 USS_MAP_OBJ_01: 8 PF_PP
 SG_ MessageCounter_Map_Obj_01 : 54|2@1+ (1,0) [0|3] "" Vector__XXX
 SG_ CRC_01_Map_Obj_11 m1 : 56|8@1+ (1,0) [0|255] "" Vector__XXX
 SG_ CRC_00_Map_Obj_01 m0 : 56|8@1+ (1,0) [0|255] "" Vector__XXX
 SG_ MAP_11_ObjectType m1 : 44|2@1+ (1,0) [0|15] ""  HMI
 SG_ MAP_11_Obj_ID m1 : 46|8@1+ (1,0) [0|255] ""  HMI
 SG_ MAP_11_ExistProbability m1 : 20|3@1+ (1,0) [0|15] ""  HMI
 SG_ MAP_11_2ndPointY m1 : 33|10@1- (2,0) [-1024|1022] "cm"  HMI
 SG_ MAP_11_2ndPointX m1 : 23|10@1- (2,0) [-1024|1022] "cm"  HMI
 SG_ MAP_11_1stPointY m1 : 10|10@1- (2,0) [-1024|1022] "cm"  HMI
 SG_ MAP_11_1stPointX m1 : 0|10@1- (2,0) [-1024|1022] "cm"  HMI
 SG_ Multiplex_ID_01 M : 43|1@1+ (1,0) [0|1] ""  HMI
 SG_ MAP_01_ObjectType m0 : 44|2@1+ (1,0) [0|15] ""  HMI
 SG_ MAP_01_Obj_ID m0 : 46|8@1+ (1,0) [0|255] ""  HMI
 SG_ MAP_01_2ndPointY m0 : 33|10@1- (2,0) [-1024|1022] "cm"  HMI
 SG_ MAP_01_2ndPointX m0 : 23|10@1- (2,0) [-1024|1022] "cm"  HMI
 SG_ MAP_01_ExistProbability m0 : 20|3@1+ (1,0) [0|15] ""  HMI
 SG_ MAP_01_1stPointY m0 : 10|10@1- (2,0) [-1024|1022] "cm"  HMI
 SG_ MAP_01_1stPointX m0 : 0|10@1- (2,0) [-1024|1022] "cm"  HMI

BO_ 2564456442 msgD_RQ_PF_PP_Phys: 8 CUST
 SG_ sigD_RQ_PF_PP_Phys : 0|64@1+ (1,0) [0|0] ""  USS_ECU

BO_ 2564487807 msgD_RS_PF_PP: 8 USS_ECU
 SG_ sigD_RS_PF_PP : 0|64@1+ (1,0) [0|0] ""  USS_ECU

CM_ BO_ 3221225472 "This is a message for not used signals, created by Vector CANdb++ DBC OLE DB Provider.";
CM_ SG_ 3221225472 sens11De3Distance "Distance of the Direct Echo";
CM_ SG_ 3221225472 sens10De3Distance "Distance of the Direct Echo";
CM_ SG_ 3221225472 sens09De3Distance "Distance of the Direct Echo";
CM_ SG_ 3221225472 sens06De3Distance "Distance of the Direct Echo";
CM_ SG_ 3221225472 sens05De3Distance "Distance of the Direct Echo";
CM_ SG_ 3221225472 sens03De3Distance "Distance of the Direct Echo";
CM_ SG_ 3221225472 sens02De3Distance "Distance of the Direct Echo";
CM_ SG_ 3221225472 sens04De3Distance "Distance of the Direct Echo";
CM_ SG_ 3221225472 sens01De3Distance "Distance of the Direct Echo";
CM_ SG_ 400 sens01CeRight2Distance "Distance of the Cross Echo";
CM_ SG_ 400 sens01CeRight1Distance "Distance of the Cross Echo";
CM_ SG_ 401 sens02CeRight2Distance "Distance of the Cross Echo";
CM_ SG_ 401 sens02CeRight1Distance "Distance of the Cross Echo";
CM_ SG_ 401 sens02CeLeft2Distance "Distance of the Cross Echo";
CM_ SG_ 401 sens02CeLeft1Distance "Distance of the Cross Echo";
CM_ SG_ 402 sens03CeRight2Distance "Distance of the Cross Echo";
CM_ SG_ 402 sens03CeRight1Distance "Distance of the Cross Echo";
CM_ SG_ 402 sens03CeLeft2Distance "Distance of the Cross Echo";
CM_ SG_ 402 sens03CeLeft1Distance "Distance of the Cross Echo";
CM_ SG_ 403 sens04CeRight2Distance "Distance of the Cross Echo";
CM_ SG_ 403 sens04CeRight1Distance "Distance of the Cross Echo";
CM_ SG_ 403 sens04CeLeft2Distance "Distance of the Cross Echo";
CM_ SG_ 403 sens04CeLeft1Distance "Distance of the Cross Echo";
CM_ SG_ 404 sens05CeRight2Distance "Distance of the Cross Echo";
CM_ SG_ 404 sens05CeRight1Distance "Distance of the Cross Echo";
CM_ SG_ 404 sens05CeLeft2Distance "Distance of the Cross Echo";
CM_ SG_ 404 sens05CeLeft1Distance "Distance of the Cross Echo";
CM_ SG_ 405 sens06CeLeft2Distance "Distance of the Cross Echo";
CM_ SG_ 405 sens06CeLeft1Distance "Distance of the Cross Echo";
CM_ SG_ 406 sens07CeRight2Distance "Distance of the Cross Echo";
CM_ SG_ 406 sens07CeRight1Distance "Distance of the Cross Echo";
CM_ SG_ 407 sens08CeRight2Distance "Distance of the Cross Echo";
CM_ SG_ 407 sens08CeRight1Distance "Distance of the Cross Echo";
CM_ SG_ 407 sens08CeLeft2Distance "Distance of the Cross Echo";
CM_ SG_ 407 sens08CeLeft1Distance "Distance of the Cross Echo";
CM_ SG_ 408 sens09CeRight2Distance "Distance of the Cross Echo";
CM_ SG_ 408 sens09CeRight1Distance "Distance of the Cross Echo";
CM_ SG_ 408 sens09CeLeft2Distance "Distance of the Cross Echo";
CM_ SG_ 408 sens09CeLeft1Distance "Distance of the Cross Echo";
CM_ SG_ 409 sens10CeRight2Distance "Distance of the Cross Echo";
CM_ SG_ 409 sens10CeRight1Distance "Distance of the Cross Echo";
CM_ SG_ 409 sens10CeLeft2Distance "Distance of the Cross Echo";
CM_ SG_ 409 sens10CeLeft1Distance "Distance of the Cross Echo";
CM_ SG_ 410 sens11CeRight2Distance "Distance of the Cross Echo";
CM_ SG_ 410 sens11CeRight1Distance "Distance of the Cross Echo";
CM_ SG_ 410 sens11CeLeft2Distance "Distance of the Cross Echo";
CM_ SG_ 410 sens11CeLeft1Distance "Distance of the Cross Echo";
CM_ SG_ 411 sens12CeLeft2Distance "Distance of the Cross Echo";
CM_ SG_ 411 sens12CeLeft1Distance "Distance of the Cross Echo";
CM_ SG_ 378 sens11De1FilteredDistance "Distance of the Direct Echo";
CM_ SG_ 378 sens11De2Distance "Distance of the Direct Echo";
CM_ SG_ 378 sens11De1Distance "Distance of the Direct Echo";
CM_ SG_ 377 sens10De1FilteredDistance "Distance of the Direct Echo";
CM_ SG_ 377 sens10De2Distance "Distance of the Direct Echo";
CM_ SG_ 377 sens10De1Distance "Distance of the Direct Echo";
CM_ SG_ 379 sens12De1FilteredDistance "Distance of the Direct Echo";
CM_ SG_ 379 sens12De1Distance "Distance of the Direct Echo";
CM_ SG_ 376 sens09De1FilteredDistance "Distance of the Direct Echo";
CM_ SG_ 376 sens09De2Distance "Distance of the Direct Echo";
CM_ SG_ 376 sens09De1Distance "Distance of the Direct Echo";
CM_ SG_ 375 sens08De1FilteredDistance "Distance of the Direct Echo";
CM_ SG_ 375 sens08De1Distance "Distance of the Direct Echo";
CM_ SG_ 374 sens07De1FilteredDistance "Distance of the Direct Echo";
CM_ SG_ 374 sens07De1Distance "Distance of the Direct Echo";
CM_ SG_ 373 sens06De1FilteredDistance "Distance of the Direct Echo";
CM_ SG_ 373 sens06De2Distance "Distance of the Direct Echo";
CM_ SG_ 373 sens06De1Distance "Distance of the Direct Echo";
CM_ SG_ 372 sens05De1Distance "Distance of the Direct Echo";
CM_ SG_ 372 sens05De2Distance "Distance of the Direct Echo";
CM_ SG_ 372 sens05De1FilteredDistance "Distance of the Direct Echo";
CM_ SG_ 370 sens03De1FilteredDistance "Distance of the Direct Echo";
CM_ SG_ 370 sens03De2Distance "Distance of the Direct Echo";
CM_ SG_ 370 sens03De1Distance "Distance of the Direct Echo";
CM_ SG_ 369 sens02De2Distance "Distance of the Direct Echo";
CM_ SG_ 369 sens02De1Distance "Distance of the Direct Echo";
CM_ SG_ 369 sens02De1FilteredDistance "Distance of the Direct Echo";
CM_ SG_ 371 sens04De1FilteredDistance "Distance of the Direct Echo";
CM_ SG_ 371 sens04De1Distance "Distance of the Direct Echo";
CM_ SG_ 371 sens04De2Distance "Distance of the Direct Echo";
CM_ SG_ 368 sens01De1FilteredDistance "Distance of the Direct Echo";
CM_ SG_ 368 sens01De1Distance "Distance of the Direct Echo";
CM_ SG_ 368 sens01De2Distance "Distance of the Direct Echo";
CM_ BO_ 393 "MAP: infos for objects 10 and 20";
CM_ BO_ 392 "MAP: infos for objects 9 and 19";
CM_ BO_ 391 "MAP: infos for objects 8 and 18";
CM_ BO_ 390 "MAP: infos for objects 7 and 17";
CM_ BO_ 389 "MAP: infos for objects 6 and 16";
CM_ BO_ 388 "MAP: infos for objects 5 and 15";
CM_ BO_ 387 "MAP: infos for objects 4 and 14";
CM_ BO_ 386 "MAP: infos for objects 3 and 13";
CM_ BO_ 385 "MAP: infos for objects 2 and 12";
CM_ BO_ 384 "MAP: infos for objects 1 and 11";
CM_ SG_ 2564456442 sigD_RQ_PF_PP_Phys "Diagnostic request";
CM_ SG_ 2564487807 sigD_RS_PF_PP "Diagnostic response";
BA_DEF_  "BusType" STRING ;
BA_DEF_  "BaudRate" FLOAT 1000 1000000;
BA_DEF_ BO_  "GenMsgSendType" ENUM  "cyclic","spontaneous","cyclicIfActive","spontaneousWithDelay";
BA_DEF_ BO_  "GenMsgCycleTime" FLOAT 0 300000;
BA_DEF_ BO_  "GenMsgDelayTime" FLOAT 0 300000;
BA_DEF_ SG_  "GenSigStartValue" FLOAT -1.79769313486232E+308 1.84467440737096E+019;
BA_DEF_DEF_  "BusType" "";
BA_DEF_DEF_  "BaudRate" 1000;
BA_DEF_DEF_  "GenMsgSendType" "";
BA_DEF_DEF_  "GenMsgCycleTime" 0;
BA_DEF_DEF_  "GenMsgDelayTime" 0;
BA_DEF_DEF_  "GenSigStartValue" 0;
BA_ "BaudRate" 500000;
BA_ "BusType" "CAN";
BA_ "GenMsgSendType" BO_ 400 0;
BA_ "GenMsgCycleTime" BO_ 400 100;
BA_ "GenMsgSendType" BO_ 401 0;
BA_ "GenMsgCycleTime" BO_ 401 100;
BA_ "GenMsgSendType" BO_ 402 0;
BA_ "GenMsgCycleTime" BO_ 402 100;
BA_ "GenMsgSendType" BO_ 403 0;
BA_ "GenMsgCycleTime" BO_ 403 100;
BA_ "GenMsgSendType" BO_ 404 0;
BA_ "GenMsgCycleTime" BO_ 404 100;
BA_ "GenMsgSendType" BO_ 405 0;
BA_ "GenMsgCycleTime" BO_ 405 100;
BA_ "GenMsgSendType" BO_ 406 0;
BA_ "GenMsgCycleTime" BO_ 406 100;
BA_ "GenMsgSendType" BO_ 407 0;
BA_ "GenMsgCycleTime" BO_ 407 100;
BA_ "GenMsgSendType" BO_ 408 0;
BA_ "GenMsgCycleTime" BO_ 408 100;
BA_ "GenMsgSendType" BO_ 409 0;
BA_ "GenMsgCycleTime" BO_ 409 100;
BA_ "GenMsgSendType" BO_ 410 0;
BA_ "GenMsgCycleTime" BO_ 410 100;
BA_ "GenMsgSendType" BO_ 411 0;
BA_ "GenMsgCycleTime" BO_ 411 100;
BA_ "GenMsgSendType" BO_ 380 0;
BA_ "GenMsgCycleTime" BO_ 380 40;
BA_ "GenMsgSendType" BO_ 2337275904 0;
BA_ "GenMsgCycleTime" BO_ 2337275904 40;
BA_ "GenMsgSendType" BO_ 378 0;
BA_ "GenMsgCycleTime" BO_ 378 40;
BA_ "GenMsgCycleTime" BO_ 377 40;
BA_ "GenMsgSendType" BO_ 377 0;
BA_ "GenMsgCycleTime" BO_ 379 40;
BA_ "GenMsgSendType" BO_ 379 0;
BA_ "GenMsgCycleTime" BO_ 376 40;
BA_ "GenMsgSendType" BO_ 376 0;
BA_ "GenMsgCycleTime" BO_ 375 40;
BA_ "GenMsgSendType" BO_ 375 0;
BA_ "GenMsgCycleTime" BO_ 374 40;
BA_ "GenMsgSendType" BO_ 374 0;
BA_ "GenMsgCycleTime" BO_ 373 40;
BA_ "GenMsgSendType" BO_ 373 0;
BA_ "GenMsgCycleTime" BO_ 372 40;
BA_ "GenMsgSendType" BO_ 372 0;
BA_ "GenMsgCycleTime" BO_ 370 40;
BA_ "GenMsgSendType" BO_ 370 0;
BA_ "GenMsgCycleTime" BO_ 369 40;
BA_ "GenMsgSendType" BO_ 369 0;
BA_ "GenMsgCycleTime" BO_ 371 40;
BA_ "GenMsgSendType" BO_ 371 0;
BA_ "GenMsgSendType" BO_ 368 0;
BA_ "GenMsgCycleTime" BO_ 368 40;
BA_ "GenMsgSendType" BO_ 2564456442 1;
BA_ "GenMsgSendType" BO_ 2564487807 1;
BA_ "GenSigStartValue" SG_ 380 OutsideTemperatureInfo 40;
BA_ "GenSigStartValue" SG_ 2337275904 OutsideTemperature 40;
BA_ "GenSigStartValue" SG_ 384 MAP_01_1stPointX 50;
VAL_ 3221225472 sens11Amplitude3 63 "Sna" 62 "No object" 61 "Presence detection" ;
VAL_ 3221225472 sens11De3Distance 1023 "Sna" 1022 "SensorFaulted" 1021 "SensorBlind" 1003 "NoObject" 1002 "PresenceDetection" ;
VAL_ 3221225472 sens10Amplitude3 63 "Sna" 62 "No object" 61 "Presence detection" ;
VAL_ 3221225472 sens10De3Distance 1023 "Sna" 1022 "SensorFaulted" 1021 "SensorBlind" 1003 "NoObject" 1002 "PresenceDetection" ;
VAL_ 3221225472 sens12Amplitude3 63 "Sna" 62 "No object" 61 "Presence detection" ;
VAL_ 3221225472 sens12De3Distance 1023 "Sna" 1022 "SensorFaulted" 1021 "SensorBlind" 1003 "NoObject" 1002 "PresenceDetection" ;
VAL_ 3221225472 sens09Amplitude3 63 "Sna" 62 "No object" 61 "Presence detection" ;
VAL_ 3221225472 sens09De3Distance 1023 "Sna" 1022 "SensorFaulted" 1021 "SensorBlind" 1003 "NoObject" 1002 "PresenceDetection" ;
VAL_ 3221225472 sens08Amplitude3 63 "Sna" 62 "No object" 61 "Presence detection" ;
VAL_ 3221225472 sens08De3Distance 1023 "Sna" 1022 "SensorFaulted" 1021 "SensorBlind" 1003 "NoObject" 1002 "PresenceDetection" ;
VAL_ 3221225472 sens07Amplitude3 63 "Sna" 62 "No object" 61 "Presence detection" ;
VAL_ 3221225472 sens07De3Distance 1023 "Sna" 1022 "SensorFaulted" 1021 "SensorBlind" 1003 "NoObject" 1002 "PresenceDetection" ;
VAL_ 3221225472 sens06Amplitude3 63 "Sna" 62 "No object" 61 "Presence detection" ;
VAL_ 3221225472 sens06De3Distance 1023 "Sna" 1022 "SensorFaulted" 1021 "SensorBlind" 1003 "NoObject" 1002 "PresenceDetection" ;
VAL_ 3221225472 sens05Amplitude3 63 "Sna" 62 "No object" 61 "Presence detection" ;
VAL_ 3221225472 sens05De3Distance 1023 "Sna" 1022 "SensorFaulted" 1021 "SensorBlind" 1003 "NoObject" 1002 "PresenceDetection" ;
VAL_ 3221225472 sens03De3Distance 1023 "Sna" 1022 "SensorFaulted" 1021 "SensorBlind" 1003 "NoObject" 1002 "PresenceDetection" ;
VAL_ 3221225472 sens03Amplitude3 63 "Sna" 62 "No object" 61 "Presence detection" ;
VAL_ 3221225472 sens02Amplitude3 63 "Sna" 62 "No object" 61 "Presence detection" ;
VAL_ 3221225472 sens02De3Distance 1023 "Sna" 1022 "SensorFaulted" 1021 "SensorBlind" 1003 "NoObject" 1002 "PresenceDetection" ;
VAL_ 3221225472 sens04Amplitude3 63 "Sna" 62 "No object" 61 "Presence detection" ;
VAL_ 3221225472 sens04De3Distance 1023 "Sna" 1022 "SensorFaulted" 1021 "SensorBlind" 1003 "NoObject" 1002 "PresenceDetection" ;
VAL_ 3221225472 sens01Amplitude3 63 "Sna" 62 "No object" 61 "Presence detection" ;
VAL_ 3221225472 sens01De3Distance 1023 "Sna" 1022 "SensorFaulted" 1021 "SensorBlind" 1003 "NoObject" 1002 "PresenceDetection" ;
VAL_ 3221225472 MAP_13_NewObj 1 "NewObject" 0 "OldObject" ;
VAL_ 3221225472 MAP_03_NewObj 1 "NewObject" 0 "OldObject" ;
VAL_ 3221225472 MAP_12_NewObj 1 "NewObject" 0 "OldObject" ;
VAL_ 3221225472 MAP_02_NewObj 1 "NewObject" 0 "OldObject" ;
VAL_ 3221225472 MAP_11_NewObj 1 "NewObject" 0 "OldObject" ;
VAL_ 3221225472 MAP_01_NewObj 1 "NewObject" 0 "OldObject" ;
VAL_ 3221225472 MAP_20_NewObj 1 "NewObject" 0 "OldObject" ;
VAL_ 3221225472 MAP_10_NewObj 1 "NewObject" 0 "OldObject" ;
VAL_ 3221225472 MAP_19_NewObj 1 "NewObject" 0 "OldObject" ;
VAL_ 3221225472 MAP_09_NewObj 1 "NewObject" 0 "OldObject" ;
VAL_ 3221225472 MAP_18_NewObj 1 "NewObject" 0 "OldObject" ;
VAL_ 3221225472 MAP_08_NewObj 1 "NewObject" 0 "OldObject" ;
VAL_ 3221225472 MAP_17_NewObj 1 "NewObject" 0 "OldObject" ;
VAL_ 3221225472 MAP_07_NewObj 1 "NewObject" 0 "OldObject" ;
VAL_ 3221225472 MAP_16_NewObj 1 "NewObject" 0 "OldObject" ;
VAL_ 3221225472 MAP_06_NewObj 1 "NewObject" 0 "OldObject" ;
VAL_ 3221225472 MAP_15_NewObj 1 "NewObject" 0 "OldObject" ;
VAL_ 3221225472 MAP_05_NewObj 1 "NewObject" 0 "OldObject" ;
VAL_ 3221225472 MAP_14_NewObj 1 "NewObject" 0 "OldObject" ;
VAL_ 3221225472 MAP_04_NewObj 1 "NewObject" 0 "OldObject" ;
VAL_ 400 sens01CeRightAmplitude2 63 "Sna" 62 "No object" 61 "Presence detection" ;
VAL_ 400 sens01CeRightAmplitude1 63 "Sna" 62 "No object" 61 "Presence detection" ;
VAL_ 400 sens01CeRight2Distance 1023 "Sna" 1022 "SensorFaulted" 1021 "SensorBlind" 1003 "NoObject" 1002 "PresenceDetection" ;
VAL_ 400 sens01CeRight1Distance 1023 "Sna" 1022 "SensorFaulted" 1021 "SensorBlind" 1003 "NoObject" 1002 "PresenceDetection" ;
VAL_ 400 sens01CeLeftAmplitude2 63 "Sna" 62 "No object" 61 "Presence detection" ;
VAL_ 400 sens01CeLeftAmplitude1 63 "Sna" 62 "No object" 61 "Presence detection" ;
VAL_ 400 sens01CeLeft2Distance 1023 "Sna" 1022 "SensorFaulted" 1021 "SensorBlind" 1003 "NoObject" 1002 "PresenceDetection" ;
VAL_ 400 sens01CeLeft1Distance 1023 "Sna" 1022 "SensorFaulted" 1021 "SensorBlind" 1003 "NoObject" 1002 "PresenceDetection" ;
VAL_ 401 sens02CeRightAmplitude2 63 "Sna" 62 "No object" 61 "Presence detection" ;
VAL_ 401 sens02CeRightAmplitude1 63 "Sna" 62 "No object" 61 "Presence detection" ;
VAL_ 401 sens02CeRight2Distance 1023 "Sna" 1022 "SensorFaulted" 1021 "SensorBlind" 1003 "NoObject" 1002 "PresenceDetection" ;
VAL_ 401 sens02CeRight1Distance 1023 "Sna" 1022 "SensorFaulted" 1021 "SensorBlind" 1003 "NoObject" 1002 "PresenceDetection" ;
VAL_ 401 sens02CeLeftAmplitude2 63 "Sna" 62 "No object" 61 "Presence detection" ;
VAL_ 401 sens02CeLeftAmplitude1 63 "Sna" 62 "No object" 61 "Presence detection" ;
VAL_ 401 sens02CeLeft2Distance 1023 "Sna" 1022 "SensorFaulted" 1021 "SensorBlind" 1003 "NoObject" 1002 "PresenceDetection" ;
VAL_ 401 sens02CeLeft1Distance 1023 "Sna" 1022 "SensorFaulted" 1021 "SensorBlind" 1003 "NoObject" 1002 "PresenceDetection" ;
VAL_ 402 sens03CeRightAmplitude2 63 "Sna" 62 "No object" 61 "Presence detection" ;
VAL_ 402 sens03CeRightAmplitude1 63 "Sna" 62 "No object" 61 "Presence detection" ;
VAL_ 402 sens03CeRight2Distance 1023 "Sna" 1022 "SensorFaulted" 1021 "SensorBlind" 1003 "NoObject" 1002 "PresenceDetection" ;
VAL_ 402 sens03CeRight1Distance 1023 "Sna" 1022 "SensorFaulted" 1021 "SensorBlind" 1003 "NoObject" 1002 "PresenceDetection" ;
VAL_ 402 sens03CeLeftAmplitude2 63 "Sna" 62 "No object" 61 "Presence detection" ;
VAL_ 402 sens03CeLeftAmplitude1 63 "Sna" 62 "No object" 61 "Presence detection" ;
VAL_ 402 sens03CeLeft2Distance 1023 "Sna" 1022 "SensorFaulted" 1021 "SensorBlind" 1003 "NoObject" 1002 "PresenceDetection" ;
VAL_ 402 sens03CeLeft1Distance 1023 "Sna" 1022 "SensorFaulted" 1021 "SensorBlind" 1003 "NoObject" 1002 "PresenceDetection" ;
VAL_ 403 sens04CeRightAmplitude2 63 "Sna" 62 "No object" 61 "Presence detection" ;
VAL_ 403 sens04CeRightAmplitude1 63 "Sna" 62 "No object" 61 "Presence detection" ;
VAL_ 403 sens04CeRight2Distance 1023 "Sna" 1022 "SensorFaulted" 1021 "SensorBlind" 1003 "NoObject" 1002 "PresenceDetection" ;
VAL_ 403 sens04CeRight1Distance 1023 "Sna" 1022 "SensorFaulted" 1021 "SensorBlind" 1003 "NoObject" 1002 "PresenceDetection" ;
VAL_ 403 sens04CeLeftAmplitude2 63 "Sna" 62 "No object" 61 "Presence detection" ;
VAL_ 403 sens04CeLeftAmplitude1 63 "Sna" 62 "No object" 61 "Presence detection" ;
VAL_ 403 sens04CeLeft2Distance 1023 "Sna" 1022 "SensorFaulted" 1021 "SensorBlind" 1003 "NoObject" 1002 "PresenceDetection" ;
VAL_ 403 sens04CeLeft1Distance 1023 "Sna" 1022 "SensorFaulted" 1021 "SensorBlind" 1003 "NoObject" 1002 "PresenceDetection" ;
VAL_ 404 sens05CeRightAmplitude2 63 "Sna" 62 "No object" 61 "Presence detection" ;
VAL_ 404 sens05CeRightAmplitude1 63 "Sna" 62 "No object" 61 "Presence detection" ;
VAL_ 404 sens05CeRight2Distance 1023 "Sna" 1022 "SensorFaulted" 1021 "SensorBlind" 1003 "NoObject" 1002 "PresenceDetection" ;
VAL_ 404 sens05CeRight1Distance 1023 "Sna" 1022 "SensorFaulted" 1021 "SensorBlind" 1003 "NoObject" 1002 "PresenceDetection" ;
VAL_ 404 sens05CeLeftAmplitude2 63 "Sna" 62 "No object" 61 "Presence detection" ;
VAL_ 404 sens05CeLeftAmplitude1 63 "Sna" 62 "No object" 61 "Presence detection" ;
VAL_ 404 sens05CeLeft2Distance 1023 "Sna" 1022 "SensorFaulted" 1021 "SensorBlind" 1003 "NoObject" 1002 "PresenceDetection" ;
VAL_ 404 sens05CeLeft1Distance 1023 "Sna" 1022 "SensorFaulted" 1021 "SensorBlind" 1003 "NoObject" 1002 "PresenceDetection" ;
VAL_ 405 sens06CeRightAmplitude2 63 "Sna" 62 "No object" 61 "Presence detection" ;
VAL_ 405 sens06CeRightAmplitude1 63 "Sna" 62 "No object" 61 "Presence detection" ;
VAL_ 405 sens06CeRight2Distance 1023 "Sna" 1022 "SensorFaulted" 1021 "SensorBlind" 1003 "NoObject" 1002 "PresenceDetection" ;
VAL_ 405 sens06CeRight1Distance 1023 "Sna" 1022 "SensorFaulted" 1021 "SensorBlind" 1003 "NoObject" 1002 "PresenceDetection" ;
VAL_ 405 sens06CeLeftAmplitude2 63 "Sna" 62 "No object" 61 "Presence detection" ;
VAL_ 405 sens06CeLeftAmplitude1 63 "Sna" 62 "No object" 61 "Presence detection" ;
VAL_ 405 sens06CeLeft2Distance 1023 "Sna" 1022 "SensorFaulted" 1021 "SensorBlind" 1003 "NoObject" 1002 "PresenceDetection" ;
VAL_ 405 sens06CeLeft1Distance 1023 "Sna" 1022 "SensorFaulted" 1021 "SensorBlind" 1003 "NoObject" 1002 "PresenceDetection" ;
VAL_ 406 sens07CeRightAmplitude2 63 "Sna" 62 "No object" 61 "Presence detection" ;
VAL_ 406 sens07CeRightAmplitude1 63 "Sna" 62 "No object" 61 "Presence detection" ;
VAL_ 406 sens07CeRight2Distance 1023 "Sna" 1022 "SensorFaulted" 1021 "SensorBlind" 1003 "NoObject" 1002 "PresenceDetection" ;
VAL_ 406 sens07CeRight1Distance 1023 "Sna" 1022 "SensorFaulted" 1021 "SensorBlind" 1003 "NoObject" 1002 "PresenceDetection" ;
VAL_ 406 sens07CeLeftAmplitude2 63 "Sna" 62 "No object" 61 "Presence detection" ;
VAL_ 406 sens07CeLeftAmplitude1 63 "Sna" 62 "No object" 61 "Presence detection" ;
VAL_ 406 sens07CeLeft2Distance 1023 "Sna" 1022 "SensorFaulted" 1021 "SensorBlind" 1003 "NoObject" 1002 "PresenceDetection" ;
VAL_ 406 sens07CeLeft1Distance 1023 "Sna" 1022 "SensorFaulted" 1021 "SensorBlind" 1003 "NoObject" 1002 "PresenceDetection" ;
VAL_ 407 sens08CeRightAmplitude2 63 "Sna" 62 "No object" 61 "Presence detection" ;
VAL_ 407 sens08CeRightAmplitude1 63 "Sna" 62 "No object" 61 "Presence detection" ;
VAL_ 407 sens08CeRight2Distance 1023 "Sna" 1022 "SensorFaulted" 1021 "SensorBlind" 1003 "NoObject" 1002 "PresenceDetection" ;
VAL_ 407 sens08CeRight1Distance 1023 "Sna" 1022 "SensorFaulted" 1021 "SensorBlind" 1003 "NoObject" 1002 "PresenceDetection" ;
VAL_ 407 sens08CeLeftAmplitude2 63 "Sna" 62 "No object" 61 "Presence detection" ;
VAL_ 407 sens08CeLeftAmplitude1 63 "Sna" 62 "No object" 61 "Presence detection" ;
VAL_ 407 sens08CeLeft2Distance 1023 "Sna" 1022 "SensorFaulted" 1021 "SensorBlind" 1003 "NoObject" 1002 "PresenceDetection" ;
VAL_ 407 sens08CeLeft1Distance 1023 "Sna" 1022 "SensorFaulted" 1021 "SensorBlind" 1003 "NoObject" 1002 "PresenceDetection" ;
VAL_ 408 sens09CeRightAmplitude2 63 "Sna" 62 "No object" 61 "Presence detection" ;
VAL_ 408 sens09CeRightAmplitude1 63 "Sna" 62 "No object" 61 "Presence detection" ;
VAL_ 408 sens09CeRight2Distance 1023 "Sna" 1022 "SensorFaulted" 1021 "SensorBlind" 1003 "NoObject" 1002 "PresenceDetection" ;
VAL_ 408 sens09CeRight1Distance 1023 "Sna" 1022 "SensorFaulted" 1021 "SensorBlind" 1003 "NoObject" 1002 "PresenceDetection" ;
VAL_ 408 sens09CeLeftAmplitude2 63 "Sna" 62 "No object" 61 "Presence detection" ;
VAL_ 408 sens09CeLeftAmplitude1 63 "Sna" 62 "No object" 61 "Presence detection" ;
VAL_ 408 sens09CeLeft2Distance 1023 "Sna" 1022 "SensorFaulted" 1021 "SensorBlind" 1003 "NoObject" 1002 "PresenceDetection" ;
VAL_ 408 sens09CeLeft1Distance 1023 "Sna" 1022 "SensorFaulted" 1021 "SensorBlind" 1003 "NoObject" 1002 "PresenceDetection" ;
VAL_ 409 sens10CeRightAmplitude2 63 "Sna" 62 "No object" 61 "Presence detection" ;
VAL_ 409 sens10CeRightAmplitude1 63 "Sna" 62 "No object" 61 "Presence detection" ;
VAL_ 409 sens10CeRight2Distance 1023 "Sna" 1022 "SensorFaulted" 1021 "SensorBlind" 1003 "NoObject" 1002 "PresenceDetection" ;
VAL_ 409 sens10CeRight1Distance 1023 "Sna" 1022 "SensorFaulted" 1021 "SensorBlind" 1003 "NoObject" 1002 "PresenceDetection" ;
VAL_ 409 sens10CeLeftAmplitude2 63 "Sna" 62 "No object" 61 "Presence detection" ;
VAL_ 409 sens10CeLeftAmplitude1 63 "Sna" 62 "No object" 61 "Presence detection" ;
VAL_ 409 sens10CeLeft2Distance 1023 "Sna" 1022 "SensorFaulted" 1021 "SensorBlind" 1003 "NoObject" 1002 "PresenceDetection" ;
VAL_ 409 sens10CeLeft1Distance 1023 "Sna" 1022 "SensorFaulted" 1021 "SensorBlind" 1003 "NoObject" 1002 "PresenceDetection" ;
VAL_ 410 sens11CeRightAmplitude2 63 "Sna" 62 "No object" 61 "Presence detection" ;
VAL_ 410 sens11CeRightAmplitude1 63 "Sna" 62 "No object" 61 "Presence detection" ;
VAL_ 410 sens11CeRight2Distance 1023 "Sna" 1022 "SensorFaulted" 1021 "SensorBlind" 1003 "NoObject" 1002 "PresenceDetection" ;
VAL_ 410 sens11CeRight1Distance 1023 "Sna" 1022 "SensorFaulted" 1021 "SensorBlind" 1003 "NoObject" 1002 "PresenceDetection" ;
VAL_ 410 sens11CeLeftAmplitude2 63 "Sna" 62 "No object" 61 "Presence detection" ;
VAL_ 410 sens11CeLeftAmplitude1 63 "Sna" 62 "No object" 61 "Presence detection" ;
VAL_ 410 sens11CeLeft2Distance 1023 "Sna" 1022 "SensorFaulted" 1021 "SensorBlind" 1003 "NoObject" 1002 "PresenceDetection" ;
VAL_ 410 sens11CeLeft1Distance 1023 "Sna" 1022 "SensorFaulted" 1021 "SensorBlind" 1003 "NoObject" 1002 "PresenceDetection" ;
VAL_ 411 sens12CeRightAmplitude2 63 "Sna" 62 "No object" 61 "Presence detection" ;
VAL_ 411 sens12CeRightAmplitude1 63 "Sna" 62 "No object" 61 "Presence detection" ;
VAL_ 411 sens12CeRight2Distance 1023 "Sna" 1022 "SensorFaulted" 1021 "SensorBlind" 1003 "NoObject" 1002 "PresenceDetection" ;
VAL_ 411 sens12CeRight1Distance 1023 "Sna" 1022 "SensorFaulted" 1021 "SensorBlind" 1003 "NoObject" 1002 "PresenceDetection" ;
VAL_ 411 sens12CeLeftAmplitude2 63 "Sna" 62 "No object" 61 "Presence detection" ;
VAL_ 411 sens12CeLeftAmplitude1 63 "Sna" 62 "No object" 61 "Presence detection" ;
VAL_ 411 sens12CeLeft2Distance 1023 "Sna" 1022 "SensorFaulted" 1021 "SensorBlind" 1003 "NoObject" 1002 "PresenceDetection" ;
VAL_ 411 sens12CeLeft1Distance 1023 "Sna" 1022 "SensorFaulted" 1021 "SensorBlind" 1003 "NoObject" 1002 "PresenceDetection" ;
VAL_ 378 sens11FilteredAmplitude1 63 "Sna" 62 "No object" 61 "Presence detection" ;
VAL_ 378 sens11Amplitude2 63 "Sna" 62 "No object" 61 "Presence detection" ;
VAL_ 378 sens11Amplitude1 63 "Sna" 62 "No object" 61 "Presence detection" ;
VAL_ 378 sens11De1FilteredDistance 1023 "Sna" 1022 "SensorFaulted" 1021 "SensorBlind" 1003 "NoObject" 1002 "PresenceDetection" ;
VAL_ 378 sens11De2Distance 1023 "Sna" 1022 "SensorFaulted" 1021 "SensorBlind" 1003 "NoObject" 1002 "PresenceDetection" ;
VAL_ 378 sens11De1Distance 1023 "Sna" 1022 "SensorFaulted" 1021 "SensorBlind" 1003 "NoObject" 1002 "PresenceDetection" ;
VAL_ 377 sens10FilteredAmplitude1 63 "Sna" 62 "No object" 61 "Presence detection" ;
VAL_ 377 sens10Amplitude2 63 "Sna" 62 "No object" 61 "Presence detection" ;
VAL_ 377 sens10Amplitude1 63 "Sna" 62 "No object" 61 "Presence detection" ;
VAL_ 377 sens10De1FilteredDistance 1023 "Sna" 1022 "SensorFaulted" 1021 "SensorBlind" 1003 "NoObject" 1002 "PresenceDetection" ;
VAL_ 377 sens10De2Distance 1023 "Sna" 1022 "SensorFaulted" 1021 "SensorBlind" 1003 "NoObject" 1002 "PresenceDetection" ;
VAL_ 377 sens10De1Distance 1023 "Sna" 1022 "SensorFaulted" 1021 "SensorBlind" 1003 "NoObject" 1002 "PresenceDetection" ;
VAL_ 379 sens12FilteredAmplitude1 63 "Sna" 62 "No object" 61 "Presence detection" ;
VAL_ 379 sens12Amplitude2 63 "Sna" 62 "No object" 61 "Presence detection" ;
VAL_ 379 sens12Amplitude1 63 "Sna" 62 "No object" 61 "Presence detection" ;
VAL_ 379 sens12De1FilteredDistance 1023 "Sna" 1022 "SensorFaulted" 1021 "SensorBlind" 1003 "NoObject" 1002 "PresenceDetection" ;
VAL_ 379 sens12De2Distance 1023 "Sna" 1022 "SensorFaulted" 1021 "SensorBlind" 1003 "NoObject" 1002 "PresenceDetection" ;
VAL_ 379 sens12De1Distance 1023 "Sna" 1022 "SensorFaulted" 1021 "SensorBlind" 1003 "NoObject" 1002 "PresenceDetection" ;
VAL_ 376 sens09FilteredAmplitude1 63 "Sna" 62 "No object" 61 "Presence detection" ;
VAL_ 376 sens09Amplitude2 63 "Sna" 62 "No object" 61 "Presence detection" ;
VAL_ 376 sens09Amplitude1 63 "Sna" 62 "No object" 61 "Presence detection" ;
VAL_ 376 sens09De1FilteredDistance 1023 "Sna" 1022 "SensorFaulted" 1021 "SensorBlind" 1003 "NoObject" 1002 "PresenceDetection" ;
VAL_ 376 sens09De2Distance 1023 "Sna" 1022 "SensorFaulted" 1021 "SensorBlind" 1003 "NoObject" 1002 "PresenceDetection" ;
VAL_ 376 sens09De1Distance 1023 "Sna" 1022 "SensorFaulted" 1021 "SensorBlind" 1003 "NoObject" 1002 "PresenceDetection" ;
VAL_ 375 sens08FilteredAmplitude1 63 "Sna" 62 "No object" 61 "Presence detection" ;
VAL_ 375 sens08Amplitude2 63 "Sna" 62 "No object" 61 "Presence detection" ;
VAL_ 375 sens08Amplitude1 63 "Sna" 62 "No object" 61 "Presence detection" ;
VAL_ 375 sens08De1FilteredDistance 1023 "Sna" 1022 "SensorFaulted" 1021 "SensorBlind" 1003 "NoObject" 1002 "PresenceDetection" ;
VAL_ 375 sens08De2Distance 1023 "Sna" 1022 "SensorFaulted" 1021 "SensorBlind" 1003 "NoObject" 1002 "PresenceDetection" ;
VAL_ 375 sens08De1Distance 1023 "Sna" 1022 "SensorFaulted" 1021 "SensorBlind" 1003 "NoObject" 1002 "PresenceDetection" ;
VAL_ 374 sens07FilteredAmplitude1 63 "Sna" 62 "No object" 61 "Presence detection" ;
VAL_ 374 sens07Amplitude2 63 "Sna" 62 "No object" 61 "Presence detection" ;
VAL_ 374 sens07Amplitude1 63 "Sna" 62 "No object" 61 "Presence detection" ;
VAL_ 374 sens07De1FilteredDistance 1023 "Sna" 1022 "SensorFaulted" 1021 "SensorBlind" 1003 "NoObject" 1002 "PresenceDetection" ;
VAL_ 374 sens07De2Distance 1023 "Sna" 1022 "SensorFaulted" 1021 "SensorBlind" 1003 "NoObject" 1002 "PresenceDetection" ;
VAL_ 374 sens07De1Distance 1023 "Sna" 1022 "SensorFaulted" 1021 "SensorBlind" 1003 "NoObject" 1002 "PresenceDetection" ;
VAL_ 373 sens06FilteredAmplitude1 63 "Sna" 62 "No object" 61 "Presence detection" ;
VAL_ 373 sens06Amplitude2 63 "Sna" 62 "No object" 61 "Presence detection" ;
VAL_ 373 sens06Amplitude1 63 "Sna" 62 "No object" 61 "Presence detection" ;
VAL_ 373 sens06De1FilteredDistance 1023 "Sna" 1022 "SensorFaulted" 1021 "SensorBlind" 1003 "NoObject" 1002 "PresenceDetection" ;
VAL_ 373 sens06De2Distance 1023 "Sna" 1022 "SensorFaulted" 1021 "SensorBlind" 1003 "NoObject" 1002 "PresenceDetection" ;
VAL_ 373 sens06De1Distance 1023 "Sna" 1022 "SensorFaulted" 1021 "SensorBlind" 1003 "NoObject" 1002 "PresenceDetection" ;
VAL_ 372 sens05De1Distance 1023 "Sna" 1022 "SensorFaulted" 1021 "SensorBlind" 1003 "NoObject" 1002 "PresenceDetection" ;
VAL_ 372 sens05FilteredAmplitude1 63 "Sna" 62 "No object" 61 "Presence detection" ;
VAL_ 372 sens05Amplitude2 63 "Sna" 62 "No object" 61 "Presence detection" ;
VAL_ 372 sens05Amplitude1 63 "Sna" 62 "No object" 61 "Presence detection" ;
VAL_ 372 sens05De2Distance 1023 "Sna" 1022 "SensorFaulted" 1021 "SensorBlind" 1003 "NoObject" 1002 "PresenceDetection" ;
VAL_ 372 sens05De1FilteredDistance 1023 "Sna" 1022 "SensorFaulted" 1021 "SensorBlind" 1003 "NoObject" 1002 "PresenceDetection" ;
VAL_ 370 sens03Amplitude2 63 "Sna" 62 "No object" 61 "Presence detection" ;
VAL_ 370 sens03FilteredAmplitude1 63 "Sna" 62 "No object" 61 "Presence detection" ;
VAL_ 370 sens03Amplitude1 63 "Sna" 62 "No object" 61 "Presence detection" ;
VAL_ 370 sens03De1FilteredDistance 1023 "Sna" 1022 "SensorFaulted" 1021 "SensorBlind" 1003 "NoObject" 1002 "PresenceDetection" ;
VAL_ 370 sens03De2Distance 1023 "Sna" 1022 "SensorFaulted" 1021 "SensorBlind" 1003 "NoObject" 1002 "PresenceDetection" ;
VAL_ 370 sens03De1Distance 1023 "Sna" 1022 "SensorFaulted" 1021 "SensorBlind" 1003 "NoObject" 1002 "PresenceDetection" ;
VAL_ 369 sens02FilteredAmplitude1 63 "Sna" 62 "No object" 61 "Presence detection" ;
VAL_ 369 sens02Amplitude2 63 "Sna" 62 "No object" 61 "Presence detection" ;
VAL_ 369 sens02Amplitude1 63 "Sna" 62 "No object" 61 "Presence detection" ;
VAL_ 369 sens02De2Distance 1023 "Sna" 1022 "SensorFaulted" 1021 "SensorBlind" 1003 "NoObject" 1002 "PresenceDetection" ;
VAL_ 369 sens02De1Distance 1023 "Sna" 1022 "SensorFaulted" 1021 "SensorBlind" 1003 "NoObject" 1002 "PresenceDetection" ;
VAL_ 369 sens02De1FilteredDistance 1023 "Sna" 1022 "SensorFaulted" 1021 "SensorBlind" 1003 "NoObject" 1002 "PresenceDetection" ;
VAL_ 371 sens04FilteredAmplitude1 63 "Sna" 62 "No object" 61 "Presence detection" ;
VAL_ 371 sens04Amplitude2 63 "Sna" 62 "No object" 61 "Presence detection" ;
VAL_ 371 sens04Amplitude1 63 "Sna" 62 "No object" 61 "Presence detection" ;
VAL_ 371 sens04De1FilteredDistance 1023 "Sna" 1022 "SensorFaulted" 1021 "SensorBlind" 1003 "NoObject" 1002 "PresenceDetection" ;
VAL_ 371 sens04De1Distance 1023 "Sna" 1022 "SensorFaulted" 1021 "SensorBlind" 1003 "NoObject" 1002 "PresenceDetection" ;
VAL_ 371 sens04De2Distance 1023 "Sna" 1022 "SensorFaulted" 1021 "SensorBlind" 1003 "NoObject" 1002 "PresenceDetection" ;
VAL_ 368 sens01FilteredAmplitude1 63 "Sna" 62 "No object" 61 "Presence detection" ;
VAL_ 368 sens01Amplitude2 63 "Sna" 62 "No object" 61 "Presence detection" ;
VAL_ 368 sens01Amplitude1 63 "Sna" 62 "No object" 61 "Presence detection" ;
VAL_ 368 sens01De1FilteredDistance 1023 "Sna" 1022 "SensorFaulted" 1021 "SensorBlind" 1003 "NoObject" 1002 "PresenceDetection" ;
VAL_ 368 sens01De1Distance 1023 "Sna" 1022 "SensorFaulted" 1021 "SensorBlind" 1003 "NoObject" 1002 "PresenceDetection" ;
VAL_ 368 sens01De2Distance 1023 "Sna" 1022 "SensorFaulted" 1021 "SensorBlind" 1003 "NoObject" 1002 "PresenceDetection" ;
VAL_ 393 MAP_20_ObjectType 2 "Line" 1 "Point" 0 "None" ;
VAL_ 393 MAP_20_ExistProbability 5 "100%" 4 "80%" 3 "60%" 2 "40%" 1 "20%" 0 "0%" ;
VAL_ 393 MAP_10_ObjectType 2 "Line" 1 "Point" 0 "None" ;
VAL_ 393 MAP_10_ExistProbability 5 "100%" 4 "80%" 3 "60%" 2 "40%" 1 "20%" 0 "0%" ;
VAL_ 392 MAP_19_ObjectType 2 "Line" 1 "Point" 0 "None" ;
VAL_ 392 MAP_19_ExistProbability 5 "100%" 4 "80%" 3 "60%" 2 "40%" 1 "20%" 0 "0%" ;
VAL_ 392 MAP_09_ObjectType 2 "Line" 1 "Point" 0 "None" ;
VAL_ 392 MAP_09_ExistProbability 5 "100%" 4 "80%" 3 "60%" 2 "40%" 1 "20%" 0 "0%" ;
VAL_ 391 MAP_18_ObjectType 2 "Line" 1 "Point" 0 "None" ;
VAL_ 391 MAP_18_ExistProbability 5 "100%" 4 "80%" 3 "60%" 2 "40%" 1 "20%" 0 "0%" ;
VAL_ 391 MAP_08_ObjectType 2 "Line" 1 "Point" 0 "None" ;
VAL_ 391 MAP_08_ExistProbability 5 "100%" 4 "80%" 3 "60%" 2 "40%" 1 "20%" 0 "0%" ;
VAL_ 390 MAP_17_ObjectType 2 "Line" 1 "Point" 0 "None" ;
VAL_ 390 MAP_17_ExistProbability 5 "100%" 4 "80%" 3 "60%" 2 "40%" 1 "20%" 0 "0%" ;
VAL_ 390 MAP_07_ObjectType 2 "Line" 1 "Point" 0 "None" ;
VAL_ 390 MAP_07_ExistProbability 5 "100%" 4 "80%" 3 "60%" 2 "40%" 1 "20%" 0 "0%" ;
VAL_ 389 MAP_16_ObjectType 2 "Line" 1 "Point" 0 "None" ;
VAL_ 389 MAP_16_ExistProbability 5 "100%" 4 "80%" 3 "60%" 2 "40%" 1 "20%" 0 "0%" ;
VAL_ 389 MAP_06_ObjectType 2 "Line" 1 "Point" 0 "None" ;
VAL_ 389 MAP_06_ExistProbability 5 "100%" 4 "80%" 3 "60%" 2 "40%" 1 "20%" 0 "0%" ;
VAL_ 388 MAP_15_ObjectType 2 "Line" 1 "Point" 0 "None" ;
VAL_ 388 MAP_15_ExistProbability 5 "100%" 4 "80%" 3 "60%" 2 "40%" 1 "20%" 0 "0%" ;
VAL_ 388 MAP_05_ObjectType 2 "Line" 1 "Point" 0 "None" ;
VAL_ 388 MAP_05_ExistProbability 5 "100%" 4 "80%" 3 "60%" 2 "40%" 1 "20%" 0 "0%" ;
VAL_ 387 MAP_14_ObjectType 2 "Line" 1 "Point" 0 "None" ;
VAL_ 387 MAP_14_ExistProbability 5 "100%" 4 "80%" 3 "60%" 2 "40%" 1 "20%" 0 "0%" ;
VAL_ 387 MAP_04_ObjectType 2 "Line" 1 "Point" 0 "None" ;
VAL_ 387 MAP_04_ExistProbability 5 "100%" 4 "80%" 3 "60%" 2 "40%" 1 "20%" 0 "0%" ;
VAL_ 386 MAP_13_ObjectType 2 "Line" 1 "Point" 0 "None" ;
VAL_ 386 MAP_13_ExistProbability 5 "100%" 4 "80%" 3 "60%" 2 "40%" 1 "20%" 0 "0%" ;
VAL_ 386 MAP_03_ObjectType 2 "Line" 1 "Point" 0 "None" ;
VAL_ 386 MAP_03_ExistProbability 5 "100%" 4 "80%" 3 "60%" 2 "40%" 1 "20%" 0 "0%" ;
VAL_ 385 MAP_12_ObjectType 2 "Line" 1 "Point" 0 "None" ;
VAL_ 385 MAP_12_ExistProbability 5 "100%" 4 "80%" 3 "60%" 2 "40%" 1 "20%" 0 "0%" ;
VAL_ 385 MAP_02_ObjectType 2 "Line" 1 "Point" 0 "None" ;
VAL_ 385 MAP_02_ExistProbability 5 "100%" 4 "80%" 3 "60%" 2 "40%" 1 "20%" 0 "0%" ;
VAL_ 384 MAP_11_ObjectType 2 "Line" 1 "Point" 0 "None" ;
VAL_ 384 MAP_11_ExistProbability 5 "100%" 4 "80%" 3 "60%" 2 "40%" 1 "20%" 0 "0%" ;
VAL_ 384 MAP_01_ObjectType 2 "Line" 1 "Point" 0 "None" ;
VAL_ 384 MAP_01_ExistProbability 5 "100%" 4 "80%" 3 "60%" 2 "40%" 1 "20%" 0 "0%" ;
